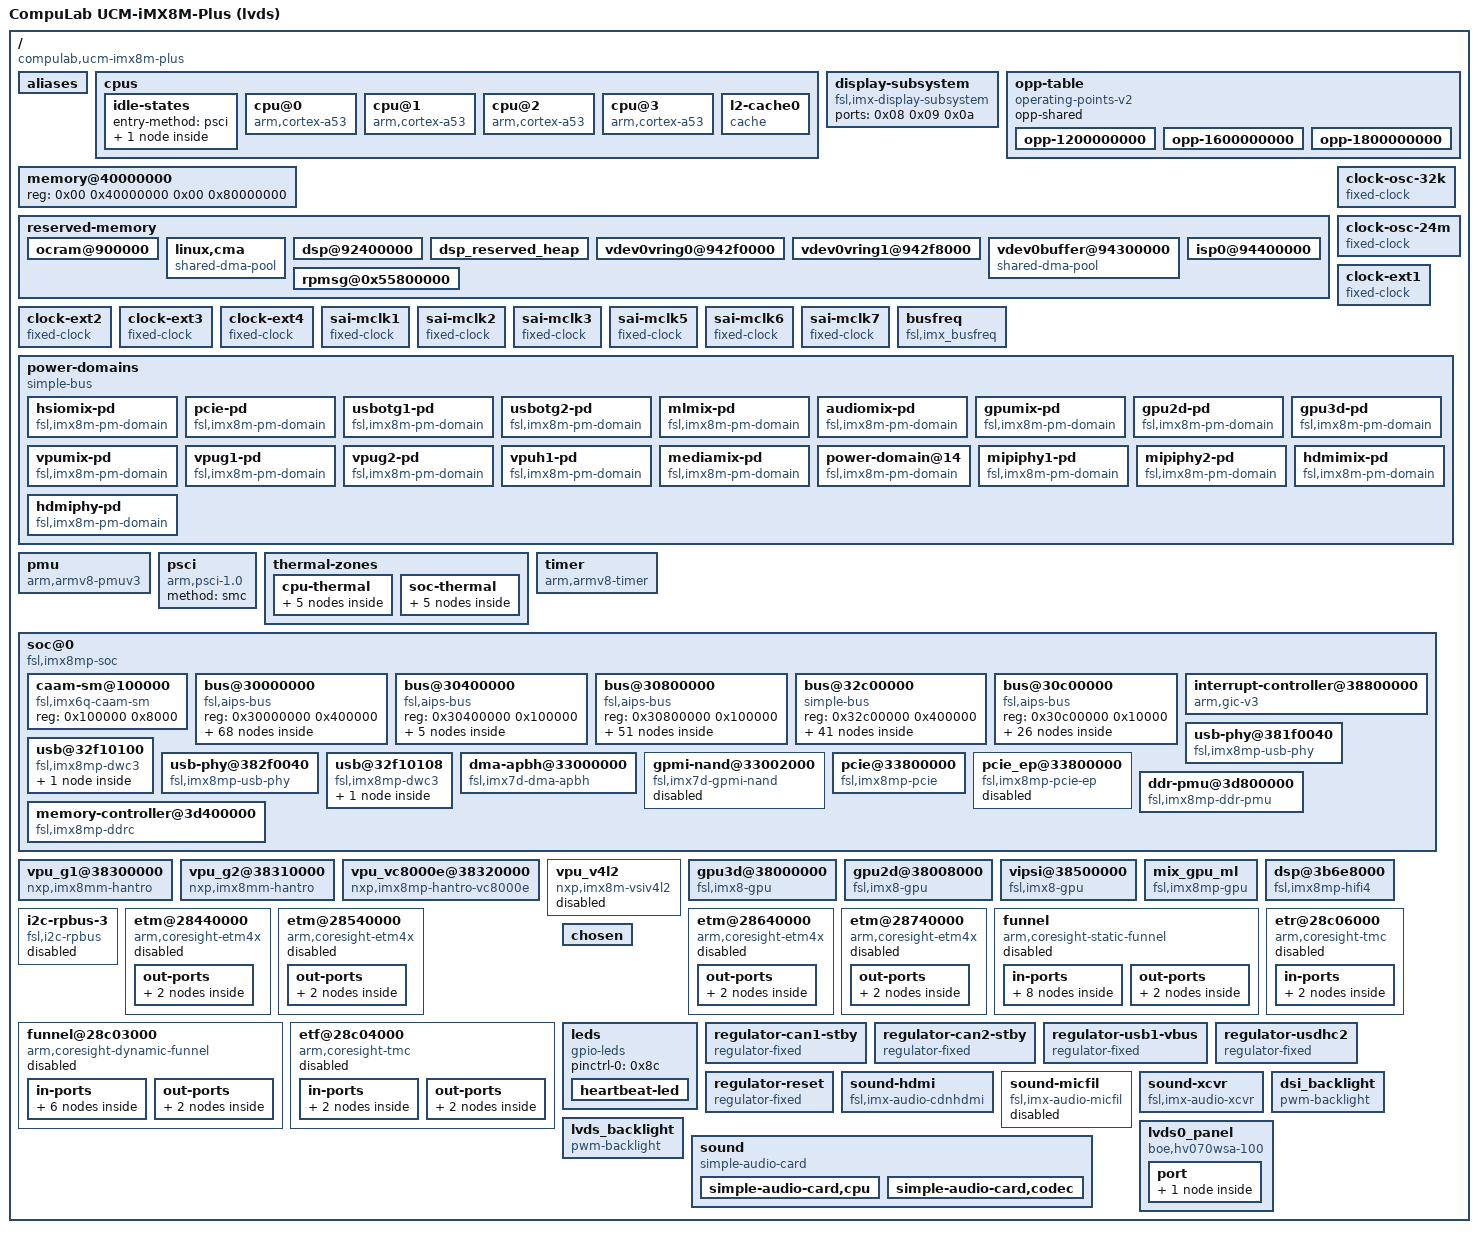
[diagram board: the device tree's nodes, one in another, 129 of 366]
# dtc -I dtb -O dts -o dtb/ucm-imx8m-plus-lvds.dts ucm-imx8m-plus-lvds.dtb
/dts-v1/;

/ {
	interrupt-parent = <0x01>;
	#address-cells = <0x02>;
	#size-cells = <0x02>;
	model = "CompuLab UCM-iMX8M-Plus (lvds)";
	compatible = "compulab,ucm-imx8m-plus\0fsl,imx8mp";

	aliases {
		ethernet0 = "/soc@0/bus@30800000/ethernet@30be0000";
		ethernet1 = "/soc@0/bus@30800000/ethernet@30bf0000";
		gpio0 = "/soc@0/bus@30000000/gpio@30200000";
		gpio1 = "/soc@0/bus@30000000/gpio@30210000";
		gpio2 = "/soc@0/bus@30000000/gpio@30220000";
		gpio3 = "/soc@0/bus@30000000/gpio@30230000";
		gpio4 = "/soc@0/bus@30000000/gpio@30240000";
		i2c0 = "/soc@0/bus@30800000/i2c@30a20000";
		i2c1 = "/soc@0/bus@30800000/i2c@30a30000";
		i2c2 = "/soc@0/bus@30800000/i2c@30a40000";
		i2c3 = "/soc@0/bus@30800000/i2c@30a50000";
		i2c4 = "/soc@0/bus@30800000/i2c@30ad0000";
		i2c5 = "/soc@0/bus@30800000/i2c@30ae0000";
		mmc0 = "/soc@0/bus@30800000/mmc@30b40000";
		mmc1 = "/soc@0/bus@30800000/mmc@30b50000";
		mmc2 = "/soc@0/bus@30800000/mmc@30b60000";
		serial0 = "/soc@0/bus@30800000/serial@30860000";
		serial1 = "/soc@0/bus@30800000/serial@30890000";
		serial2 = "/soc@0/bus@30800000/serial@30880000";
		serial3 = "/soc@0/bus@30800000/serial@30a60000";
		isi0 = "/soc@0/bus@32c00000/camera/isi@32e00000";
		isi1 = "/soc@0/bus@32c00000/camera/isi@32e02000";
		csi0 = "/soc@0/bus@32c00000/camera/csi@32e40000";
		csi1 = "/soc@0/bus@32c00000/camera/csi@32e50000";
		isp0 = "/soc@0/bus@32c00000/camera/isp@32e10000";
		isp1 = "/soc@0/bus@32c00000/camera/isp@32e20000";
	};

	cpus {
		#address-cells = <0x01>;
		#size-cells = <0x00>;

		idle-states {
			entry-method = "psci";

			cpu-pd-wait {
				compatible = "arm,idle-state";
				arm,psci-suspend-param = <0x10033>;
				local-timer-stop;
				entry-latency-us = <0x3e8>;
				exit-latency-us = <0x2bc>;
				min-residency-us = <0xa8c>;
				wakeup-latency-us = <0x5dc>;
				phandle = <0x06>;
			};
		};

		cpu@0 {
			device_type = "cpu";
			compatible = "arm,cortex-a53";
			reg = <0x00>;
			clock-latency = <0xee6c>;
			clocks = <0x02 0x11f>;
			operating-points-v2 = <0x03>;
			nvmem-cells = <0x04>;
			nvmem-cell-names = "speed_grade";
			enable-method = "psci";
			next-level-cache = <0x05>;
			#cooling-cells = <0x02>;
			cpu-idle-states = <0x06>;
			cpu-supply = <0x07>;
			phandle = <0x10>;
		};

		cpu@1 {
			device_type = "cpu";
			compatible = "arm,cortex-a53";
			reg = <0x01>;
			clock-latency = <0xee6c>;
			clocks = <0x02 0x11f>;
			operating-points-v2 = <0x03>;
			enable-method = "psci";
			next-level-cache = <0x05>;
			#cooling-cells = <0x02>;
			cpu-idle-states = <0x06>;
			cpu-supply = <0x07>;
			phandle = <0x11>;
		};

		cpu@2 {
			device_type = "cpu";
			compatible = "arm,cortex-a53";
			reg = <0x02>;
			clock-latency = <0xee6c>;
			clocks = <0x02 0x11f>;
			operating-points-v2 = <0x03>;
			enable-method = "psci";
			next-level-cache = <0x05>;
			#cooling-cells = <0x02>;
			cpu-idle-states = <0x06>;
			cpu-supply = <0x07>;
			phandle = <0x12>;
		};

		cpu@3 {
			device_type = "cpu";
			compatible = "arm,cortex-a53";
			reg = <0x03>;
			clock-latency = <0xee6c>;
			clocks = <0x02 0x11f>;
			operating-points-v2 = <0x03>;
			enable-method = "psci";
			next-level-cache = <0x05>;
			#cooling-cells = <0x02>;
			cpu-idle-states = <0x06>;
			cpu-supply = <0x07>;
			phandle = <0x13>;
		};

		l2-cache0 {
			compatible = "cache";
			phandle = <0x05>;
		};
	};

	display-subsystem {
		compatible = "fsl,imx-display-subsystem";
		ports = <0x08 0x09 0x0a>;
	};

	opp-table {
		compatible = "operating-points-v2";
		opp-shared;
		phandle = <0x03>;

		opp-1200000000 {
			opp-hz = <0x00 0x47868c00>;
			opp-microvolt = <0xcf850>;
			opp-supported-hw = <0x8a0 0x07>;
			clock-latency-ns = <0x249f0>;
			opp-suspend;
		};

		opp-1600000000 {
			opp-hz = <0x00 0x5f5e1000>;
			opp-microvolt = <0xe7ef0>;
			opp-supported-hw = <0xa0 0x07>;
			clock-latency-ns = <0x249f0>;
			opp-suspend;
		};

		opp-1800000000 {
			opp-hz = <0x00 0x6b49d200>;
			opp-microvolt = <0xf4240>;
			opp-supported-hw = <0x20 0x03>;
			clock-latency-ns = <0x249f0>;
			opp-suspend;
		};
	};

	memory@40000000 {
		device_type = "memory";
		reg = <0x00 0x40000000 0x00 0x80000000>;
	};

	reserved-memory {
		#address-cells = <0x02>;
		#size-cells = <0x02>;
		ranges;

		ocram@900000 {
			no-map;
			reg = <0x00 0x900000 0x00 0x70000>;
		};

		linux,cma {
			compatible = "shared-dma-pool";
			reusable;
			size = <0x00 0x2c000000>;
			alloc-ranges = <0x00 0x40000000 0x00 0x80000000>;
			linux,cma-default;
		};

		dsp@92400000 {
			reg = <0x00 0x92400000 0x00 0x1000000>;
			no-map;
			phandle = <0x7d>;
		};

		dsp_reserved_heap {
			reg = <0x00 0x93400000 0x00 0xef0000>;
			no-map;
		};

		vdev0vring0@942f0000 {
			reg = <0x00 0x942f0000 0x00 0x8000>;
			no-map;
			phandle = <0x7b>;
		};

		vdev0vring1@942f8000 {
			reg = <0x00 0x942f8000 0x00 0x8000>;
			no-map;
			phandle = <0x7c>;
		};

		vdev0buffer@94300000 {
			compatible = "shared-dma-pool";
			reg = <0x00 0x94300000 0x00 0x100000>;
			no-map;
			phandle = <0x7a>;
		};

		isp0@94400000 {
			no-map;
			reg = <0x00 0x94400000 0x00 0x10000000>;
			phandle = <0x5a>;
		};

		rpmsg@0x55800000 {
			no-map;
			reg = <0x00 0x55800000 0x00 0x800000>;
		};
	};

	clock-osc-32k {
		compatible = "fixed-clock";
		#clock-cells = <0x00>;
		clock-frequency = <0x8000>;
		clock-output-names = "osc_32k";
		phandle = <0x1c>;
	};

	clock-osc-24m {
		compatible = "fixed-clock";
		#clock-cells = <0x00>;
		clock-frequency = <0x16e3600>;
		clock-output-names = "osc_24m";
		phandle = <0x1d>;
	};

	clock-ext1 {
		compatible = "fixed-clock";
		#clock-cells = <0x00>;
		clock-frequency = <0x7ed6b40>;
		clock-output-names = "clk_ext1";
		phandle = <0x1e>;
	};

	clock-ext2 {
		compatible = "fixed-clock";
		#clock-cells = <0x00>;
		clock-frequency = <0x7ed6b40>;
		clock-output-names = "clk_ext2";
		phandle = <0x1f>;
	};

	clock-ext3 {
		compatible = "fixed-clock";
		#clock-cells = <0x00>;
		clock-frequency = <0x7ed6b40>;
		clock-output-names = "clk_ext3";
		phandle = <0x20>;
	};

	clock-ext4 {
		compatible = "fixed-clock";
		#clock-cells = <0x00>;
		clock-frequency = <0x7ed6b40>;
		clock-output-names = "clk_ext4";
		phandle = <0x21>;
	};

	sai-mclk1 {
		compatible = "fixed-clock";
		#clock-cells = <0x00>;
		clock-frequency = <0x00>;
		clock-output-names = "sai1_mclk";
	};

	sai-mclk2 {
		compatible = "fixed-clock";
		#clock-cells = <0x00>;
		clock-frequency = <0x00>;
		clock-output-names = "sai2_mclk";
	};

	sai-mclk3 {
		compatible = "fixed-clock";
		#clock-cells = <0x00>;
		clock-frequency = <0x00>;
		clock-output-names = "sai3_mclk";
	};

	sai-mclk5 {
		compatible = "fixed-clock";
		#clock-cells = <0x00>;
		clock-frequency = <0x00>;
		clock-output-names = "sai5_mclk";
	};

	sai-mclk6 {
		compatible = "fixed-clock";
		#clock-cells = <0x00>;
		clock-frequency = <0x00>;
		clock-output-names = "sai6_mclk";
	};

	sai-mclk7 {
		compatible = "fixed-clock";
		#clock-cells = <0x00>;
		clock-frequency = <0x00>;
		clock-output-names = "sai7_mclk";
	};

	busfreq {
		compatible = "fsl,imx_busfreq";
		clocks = <0x02 0x29 0x02 0x70 0x02 0x71 0x02 0x71 0x02 0x11e 0x02 0x11d 0x02 0x30 0x02 0x32 0x02 0x3f 0x02 0x67 0x02 0x6b 0x02 0x5d 0x02 0x02 0x02 0x38 0x02 0x15>;
		clock-names = "dram_pll\0dram_alt_src\0dram_apb_src\0dram_apb_pre_div\0dram_core\0dram_alt_root\0sys_pll1_40m\0sys_pll1_100m\0sys_pll2_333m\0noc_div\0ahb_div\0main_axi_src\0osc_24m\0sys_pll1_800m\0dram_pll_div";
	};

	power-domains {
		compatible = "simple-bus";

		hsiomix-pd {
			compatible = "fsl,imx8m-pm-domain";
			active-wakeup;
			rpm-always-on;
			#power-domain-cells = <0x00>;
			domain-index = <0x00>;
			domain-name = "hsiomix";
			phandle = <0x0b>;
		};

		pcie-pd {
			compatible = "fsl,imx8m-pm-domain";
			#power-domain-cells = <0x00>;
			domain-index = <0x01>;
			domain-name = "pcie";
			parent-domains = <0x0b>;
			phandle = <0x6c>;
		};

		usbotg1-pd {
			compatible = "fsl,imx8m-pm-domain";
			#power-domain-cells = <0x00>;
			domain-index = <0x02>;
			domain-name = "usb_otg1";
			parent-domains = <0x0b>;
		};

		usbotg2-pd {
			compatible = "fsl,imx8m-pm-domain";
			#power-domain-cells = <0x00>;
			domain-index = <0x03>;
			domain-name = "usb_otg2";
			parent-domains = <0x0b>;
		};

		mlmix-pd {
			compatible = "fsl,imx8m-pm-domain";
			#power-domain-cells = <0x00>;
			domain-index = <0x04>;
			domain-name = "mlmix";
			clocks = <0x02 0x69 0x02 0x6a 0x02 0x10b>;
			phandle = <0x75>;
		};

		audiomix-pd {
			compatible = "fsl,imx8m-pm-domain";
			#power-domain-cells = <0x00>;
			domain-index = <0x05>;
			domain-name = "audiomix";
			clocks = <0x02 0x13b 0x02 0x13c>;
			phandle = <0x5f>;
		};

		gpumix-pd {
			compatible = "fsl,imx8m-pm-domain";
			#power-domain-cells = <0x00>;
			domain-index = <0x06>;
			domain-name = "gpumix";
			clocks = <0x02 0x107 0x02 0x66 0x02 0x65>;
			phandle = <0x0c>;
		};

		gpu2d-pd {
			compatible = "fsl,imx8m-pm-domain";
			#power-domain-cells = <0x00>;
			domain-index = <0x07>;
			domain-name = "gpu2d";
			parent-domains = <0x0c>;
			clocks = <0x02 0xf7>;
			phandle = <0x74>;
		};

		gpu3d-pd {
			compatible = "fsl,imx8m-pm-domain";
			#power-domain-cells = <0x00>;
			domain-index = <0x08>;
			domain-name = "gpu3d";
			parent-domains = <0x0c>;
			clocks = <0x02 0xf8 0x02 0x134>;
			phandle = <0x73>;
		};

		vpumix-pd {
			compatible = "fsl,imx8m-pm-domain";
			#power-domain-cells = <0x00>;
			domain-index = <0x09>;
			domain-name = "vpumix";
			clocks = <0x02 0x11a>;
			phandle = <0x0d>;
		};

		vpug1-pd {
			compatible = "fsl,imx8m-pm-domain";
			#power-domain-cells = <0x00>;
			domain-index = <0x0a>;
			domain-name = "vpu_g1";
			parent-domains = <0x0d>;
			clocks = <0x02 0x106>;
			phandle = <0x70>;
		};

		vpug2-pd {
			compatible = "fsl,imx8m-pm-domain";
			#power-domain-cells = <0x00>;
			domain-index = <0x0b>;
			domain-name = "vpu_g2";
			parent-domains = <0x0d>;
			clocks = <0x02 0x10a>;
			phandle = <0x71>;
		};

		vpuh1-pd {
			compatible = "fsl,imx8m-pm-domain";
			#power-domain-cells = <0x00>;
			domain-index = <0x0c>;
			domain-name = "vpu_h1";
			parent-domains = <0x0d>;
			clocks = <0x02 0x109>;
			phandle = <0x72>;
		};

		mediamix-pd {
			compatible = "fsl,imx8m-pm-domain";
			#power-domain-cells = <0x00>;
			domain-index = <0x0d>;
			domain-name = "mediamix";
			clocks = <0x02 0x10e 0x02 0x10d>;
			phandle = <0x0e>;
		};

		power-domain@14 {
			compatible = "fsl,imx8m-pm-domain";
			#power-domain-cells = <0x00>;
			domain-index = <0x0e>;
			domain-name = "ispdwp";
			parent-domains = <0x0e>;
			phandle = <0x59>;
		};

		mipiphy1-pd {
			compatible = "fsl,imx8m-pm-domain";
			#power-domain-cells = <0x00>;
			domain-index = <0x0f>;
			domain-name = "mipi_phy1";
			parent-domains = <0x0e>;
			phandle = <0x4e>;
		};

		mipiphy2-pd {
			compatible = "fsl,imx8m-pm-domain";
			#power-domain-cells = <0x00>;
			domain-index = <0x10>;
			domain-name = "mipi_phy2";
			parent-domains = <0x0e>;
			phandle = <0x5d>;
		};

		hdmimix-pd {
			compatible = "fsl,imx8m-pm-domain";
			#power-domain-cells = <0x00>;
			domain-index = <0x11>;
			domain-name = "hdmimix";
			clocks = <0x02 0x116 0x02 0x63 0x02 0xa8>;
			phandle = <0x0f>;
		};

		hdmiphy-pd {
			compatible = "fsl,imx8m-pm-domain";
			#power-domain-cells = <0x00>;
			domain-index = <0x12>;
			domain-name = "hdmi_phy";
			parent-domains = <0x0f>;
			phandle = <0x67>;
		};
	};

	pmu {
		compatible = "arm,armv8-pmuv3";
		interrupt-parent = <0x01>;
		interrupts = <0x01 0x07 0x3f04>;
		interrupt-affinity = <0x10 0x11 0x12 0x13>;
	};

	psci {
		compatible = "arm,psci-1.0";
		method = "smc";
	};

	thermal-zones {

		cpu-thermal {
			polling-delay-passive = <0xfa>;
			polling-delay = <0x7d0>;
			thermal-sensors = <0x14 0x00>;

			trips {

				trip0 {
					temperature = <0x14c08>;
					hysteresis = <0x7d0>;
					type = "passive";
					phandle = <0x15>;
				};

				trip1 {
					temperature = <0x17318>;
					hysteresis = <0x7d0>;
					type = "critical";
				};
			};

			cooling-maps {

				map0 {
					trip = <0x15>;
					cooling-device = <0x10 0xffffffff 0xffffffff 0x11 0xffffffff 0xffffffff 0x12 0xffffffff 0xffffffff 0x13 0xffffffff 0xffffffff>;
				};
			};
		};

		soc-thermal {
			polling-delay-passive = <0xfa>;
			polling-delay = <0x7d0>;
			thermal-sensors = <0x14 0x01>;

			trips {

				trip0 {
					temperature = <0x14c08>;
					hysteresis = <0x7d0>;
					type = "passive";
					phandle = <0x16>;
				};

				trip1 {
					temperature = <0x17318>;
					hysteresis = <0x7d0>;
					type = "critical";
				};
			};

			cooling-maps {

				map0 {
					trip = <0x16>;
					cooling-device = <0x10 0xffffffff 0xffffffff 0x11 0xffffffff 0xffffffff 0x12 0xffffffff 0xffffffff 0x13 0xffffffff 0xffffffff>;
				};
			};
		};
	};

	timer {
		compatible = "arm,armv8-timer";
		interrupts = <0x01 0x0d 0x3f08 0x01 0x0e 0x3f08 0x01 0x0b 0x3f08 0x01 0x0a 0x3f08>;
		clock-frequency = <0x7a1200>;
		arm,no-tick-in-suspend;
		interrupt-parent = <0x01>;
	};

	soc@0 {
		compatible = "fsl,imx8mp-soc\0simple-bus";
		#address-cells = <0x01>;
		#size-cells = <0x01>;
		ranges = <0x00 0x00 0x00 0x3e000000>;
		nvmem-cells = <0x17>;
		nvmem-cell-names = "soc_unique_id";

		caam-sm@100000 {
			compatible = "fsl,imx6q-caam-sm";
			reg = <0x100000 0x8000>;
		};

		bus@30000000 {
			compatible = "fsl,aips-bus\0simple-bus";
			reg = <0x30000000 0x400000>;
			#address-cells = <0x01>;
			#size-cells = <0x01>;
			ranges;

			gpio@30200000 {
				compatible = "fsl,imx8mp-gpio\0fsl,imx35-gpio";
				reg = <0x30200000 0x10000>;
				interrupts = <0x00 0x40 0x04 0x00 0x41 0x04>;
				clocks = <0x02 0xc1>;
				gpio-controller;
				#gpio-cells = <0x02>;
				interrupt-controller;
				#interrupt-cells = <0x02>;
				gpio-ranges = <0x18 0x00 0x05 0x1e>;
				phandle = <0x32>;
			};

			gpio@30210000 {
				compatible = "fsl,imx8mp-gpio\0fsl,imx35-gpio";
				reg = <0x30210000 0x10000>;
				interrupts = <0x00 0x42 0x04 0x00 0x43 0x04>;
				clocks = <0x02 0xc2>;
				gpio-controller;
				#gpio-cells = <0x02>;
				interrupt-controller;
				#interrupt-cells = <0x02>;
				gpio-ranges = <0x18 0x00 0x23 0x15>;
				phandle = <0x3b>;
			};

			gpio@30220000 {
				compatible = "fsl,imx8mp-gpio\0fsl,imx35-gpio";
				reg = <0x30220000 0x10000>;
				interrupts = <0x00 0x44 0x04 0x00 0x45 0x04>;
				clocks = <0x02 0xc3>;
				gpio-controller;
				#gpio-cells = <0x02>;
				interrupt-controller;
				#interrupt-cells = <0x02>;
				gpio-ranges = <0x18 0x00 0x38 0x1a 0x18 0x1a 0x90 0x04>;
			};

			gpio@30230000 {
				compatible = "fsl,imx8mp-gpio\0fsl,imx35-gpio";
				reg = <0x30230000 0x10000>;
				interrupts = <0x00 0x46 0x04 0x00 0x47 0x04>;
				clocks = <0x02 0xc4>;
				gpio-controller;
				#gpio-cells = <0x02>;
				interrupt-controller;
				#interrupt-cells = <0x02>;
				gpio-ranges = <0x18 0x00 0x52 0x20>;
				phandle = <0x37>;
			};

			gpio@30240000 {
				compatible = "fsl,imx8mp-gpio\0fsl,imx35-gpio";
				reg = <0x30240000 0x10000>;
				interrupts = <0x00 0x48 0x04 0x00 0x49 0x04>;
				clocks = <0x02 0xc5>;
				gpio-controller;
				#gpio-cells = <0x02>;
				interrupt-controller;
				#interrupt-cells = <0x02>;
				gpio-ranges = <0x18 0x00 0x72 0x1e>;
				phandle = <0x27>;
			};

			tmu@30260000 {
				compatible = "fsl,imx8mp-tmu";
				reg = <0x30260000 0x10000>;
				clocks = <0x02 0x119>;
				#thermal-sensor-cells = <0x01>;
				phandle = <0x14>;
			};

			watchdog@30280000 {
				compatible = "fsl,imx8mp-wdt\0fsl,imx21-wdt";
				reg = <0x30280000 0x10000>;
				interrupts = <0x00 0x4e 0x04>;
				clocks = <0x02 0x103>;
				status = "okay";
				pinctrl-names = "default";
				pinctrl-0 = <0x19>;
				fsl,ext-reset-output;
			};

			pinctrl@30330000 {
				compatible = "fsl,imx8mp-iomuxc";
				reg = <0x30330000 0x10000>;
				pinctrl-names = "default";
				pinctrl-0 = <0x1a>;
				phandle = <0x18>;

				hoggrp {
					fsl,pins = <0x240 0x4a0 0x00 0x00 0x00 0x400001c3 0x244 0x4a4 0x00 0x00 0x00 0x400001c3 0x24c 0x4ac 0x00 0x00 0x00 0x40000019 0x248 0x4a8 0x00 0x00 0x00 0x40000019>;
					phandle = <0x1a>;
				};

				enet1rst {
					fsl,pins = <0x3c 0x29c 0x00 0x00 0x00 0x19>;
					phandle = <0x90>;
				};

				pwm1grp {
					fsl,pins = <0x1dc 0x43c 0x00 0x01 0x00 0x116>;
					phandle = <0x22>;
				};

				pwm2grp {
					fsl,pins = <0x1d8 0x438 0x00 0x01 0x00 0x116>;
					phandle = <0x23>;
				};

				ecspi2grp {
					fsl,pins = <0x1f0 0x450 0x568 0x00 0x01 0x82 0x1f4 0x454 0x570 0x00 0x01 0x82 0x1f8 0x458 0x56c 0x00 0x01 0x82>;
					phandle = <0x25>;
				};

				ecspi2cs {
					fsl,pins = <0x1fc 0x45c 0x00 0x05 0x00 0x40000>;
					phandle = <0x26>;
				};

				eqosgrp {
					fsl,pins = <0x54 0x2b4 0x00 0x00 0x00 0x03 0x58 0x2b8 0x590 0x00 0x01 0x03 0x7c 0x2dc 0x00 0x00 0x00 0x91 0x80 0x2e0 0x00 0x00 0x00 0x91 0x84 0x2e4 0x00 0x00 0x00 0x91 0x88 0x2e8 0x00 0x00 0x00 0x91 0x78 0x2d8 0x00 0x00 0x00 0x91 0x74 0x2d4 0x00 0x00 0x00 0x91 0x68 0x2c8 0x00 0x00 0x00 0x1f 0x64 0x2c4 0x00 0x00 0x00 0x1f 0x60 0x2c0 0x00 0x00 0x00 0x1f 0x5c 0x2bc 0x00 0x00 0x00 0x1f 0x6c 0x2cc 0x00 0x00 0x00 0x1f 0x70 0x2d0 0x00 0x00 0x00 0x1f>;
					phandle = <0x4b>;
				};

				flexcan1grp {
					fsl,pins = <0x1a0 0x400 0x00 0x03 0x00 0x154 0x1ac 0x40c 0x54c 0x03 0x01 0x154>;
					phandle = <0x2c>;
				};

				flexcan2grp {
					fsl,pins = <0x1b0 0x410 0x00 0x03 0x00 0x154 0x1b4 0x414 0x550 0x03 0x01 0x154>;
					phandle = <0x2e>;
				};

				flexcan1reggrp {
					fsl,pins = <0x14 0x274 0x00 0x00 0x00 0x154>;
					phandle = <0x8d>;
				};

				flexcan2reggrp {
					fsl,pins = <0x18 0x278 0x00 0x00 0x00 0x154>;
					phandle = <0x8e>;
				};

				flexspi0grp {
					fsl,pins = <0xe0 0x340 0x00 0x01 0x00 0x1c2 0xe4 0x344 0x00 0x01 0x00 0x82 0xf8 0x358 0x00 0x01 0x00 0x82 0xfc 0x35c 0x00 0x01 0x00 0x82 0x100 0x360 0x00 0x01 0x00 0x82 0x104 0x364 0x00 0x01 0x00 0x82>;
					phandle = <0x48>;
				};

				gpioledgrp {
					fsl,pins = <0x120 0x380 0x00 0x05 0x00 0x19>;
					phandle = <0x8c>;
				};

				i2c1grp {
					fsl,pins = <0x200 0x460 0x5a4 0x00 0x02 0x400001c3 0x204 0x464 0x5a8 0x00 0x02 0x400001c3>;
					phandle = <0x30>;
				};

				i2c2grp {
					fsl,pins = <0x208 0x468 0x5ac 0x00 0x02 0x400001c3 0x20c 0x46c 0x5b0 0x00 0x02 0x400001c3>;
					phandle = <0x33>;
				};

				i2c3grp {
					fsl,pins = <0x210 0x470 0x5b4 0x00 0x04 0x400001c3 0x214 0x474 0x5b8 0x00 0x04 0x400001c3>;
					phandle = <0x35>;
				};

				i2c5grp {
					fsl,pins = <0x144 0x3a4 0x5c8 0x03 0x01 0x400001c3 0x134 0x394 0x5c4 0x03 0x01 0x400001c3>;
					phandle = <0x36>;
				};

				i2c6grp {
					fsl,pins = <0x12c 0x38c 0x5cc 0x03 0x01 0x400001c3 0x130 0x390 0x5d0 0x03 0x01 0x400001c3>;
					phandle = <0x3a>;
				};

				mipi_dsi_en {
					fsl,pins = <0x34 0x294 0x00 0x00 0x00 0x16>;
				};

				pciegrp {
					fsl,pins = <0x218 0x478 0x5a0 0x12 0x00 0x61 0xa4 0x304 0x00 0x05 0x00 0x41 0xa8 0x308 0x00 0x05 0x00 0x41>;
				};

				pmicirq {
					fsl,pins = <0x20 0x280 0x00 0x00 0x00 0x41>;
					phandle = <0x31>;
				};

				typec1grp {
					fsl,pins = <0x194 0x3f4 0x00 0x05 0x00 0x1c4>;
				};

				typec1muxgrp {
					fsl,pins = <0x198 0x3f8 0x00 0x05 0x00 0x16>;
				};

				pdmgrp {
					fsl,pins = <0x130 0x390 0x00 0x04 0x00 0xd6 0x134 0x394 0x4c0 0x04 0x03 0xd6 0x138 0x398 0x4c4 0x04 0x03 0xd6 0x13c 0x39c 0x4c8 0x04 0x03 0xd6 0x140 0x3a0 0x4cc 0x04 0x03 0xd6>;
					phandle = <0x62>;
				};

				sai2grp {
					fsl,pins = <0x1ac 0x40c 0x00 0x00 0x00 0xd6 0x1a8 0x408 0x00 0x00 0x00 0xd6 0x1b0 0x410 0x00 0x00 0x00 0xd6 0x1a4 0x404 0x00 0x00 0x00 0xd6>;
					phandle = <0x60>;
				};

				sai3grp {
					fsl,pins = <0x1c4 0x424 0x4ec 0x00 0x01 0xd6 0x1c8 0x428 0x4e8 0x00 0x01 0xd6 0x1c0 0x420 0x4e4 0x00 0x01 0xd6 0x1cc 0x42c 0x00 0x00 0x00 0xd6 0x1d0 0x430 0x4e0 0x00 0x02 0xd6 0x1b8 0x418 0x00 0x05 0x00 0xd6 0x1bc 0x41c 0x00 0x05 0x00 0xd6>;
					phandle = <0x61>;
				};

				synaptics_dsx_iogrp {
					fsl,pins = <0x38 0x298 0x00 0x00 0x00 0x16>;
				};

				uart1grp {
					fsl,pins = <0x220 0x480 0x5e8 0x00 0x04 0x140 0x224 0x484 0x00 0x00 0x00 0x140 0x230 0x490 0x00 0x01 0x00 0x140 0x234 0x494 0x5e4 0x01 0x05 0x140>;
					phandle = <0x28>;
				};

				uart2grp {
					fsl,pins = <0x228 0x488 0x5f0 0x00 0x06 0x49 0x22c 0x48c 0x00 0x00 0x00 0x49>;
					phandle = <0x2a>;
				};

				uart3grp {
					fsl,pins = <0x1e0 0x440 0x5f8 0x01 0x04 0x140 0x1e4 0x444 0x00 0x01 0x00 0x140 0x1ec 0x44c 0x5f4 0x01 0x03 0x140 0x1e8 0x448 0x00 0x01 0x00 0x140>;
					phandle = <0x29>;
				};

				usb1grp {
					fsl,pins = <0x4c 0x2ac 0x00 0x00 0x00 0x19>;
					phandle = <0x8f>;
				};

				usdhc1grp {
					fsl,pins = <0x8c 0x2ec 0x00 0x00 0x00 0x190 0x90 0x2f0 0x00 0x00 0x00 0x1d0 0x94 0x2f4 0x00 0x00 0x00 0x1d0 0x98 0x2f8 0x00 0x00 0x00 0x1d0 0x9c 0x2fc 0x00 0x00 0x00 0x1d0 0xa0 0x300 0x00 0x00 0x00 0x1d0>;
					phandle = <0x3d>;
				};

				usdhc1grp-100mhz {
					fsl,pins = <0x8c 0x2ec 0x00 0x00 0x00 0x194 0x90 0x2f0 0x00 0x00 0x00 0x1d4 0x94 0x2f4 0x00 0x00 0x00 0x1d4 0x98 0x2f8 0x00 0x00 0x00 0x1d4 0x9c 0x2fc 0x00 0x00 0x00 0x1d4 0xa0 0x300 0x00 0x00 0x00 0x1d4>;
					phandle = <0x3e>;
				};

				usdhc1grp-200mhz {
					fsl,pins = <0x8c 0x2ec 0x00 0x00 0x00 0x196 0x90 0x2f0 0x00 0x00 0x00 0x1d6 0x94 0x2f4 0x00 0x00 0x00 0x1d6 0x98 0x2f8 0x00 0x00 0x00 0x1d6 0x9c 0x2fc 0x00 0x00 0x00 0x1d6 0xa0 0x300 0x00 0x00 0x00 0x1d6>;
					phandle = <0x3f>;
				};

				usdhc2grp-gpio {
					fsl,pins = <0xbc 0x31c 0x00 0x05 0x00 0x1c4 0xd8 0x338 0x00 0x05 0x00 0x41>;
					phandle = <0x41>;
				};

				usdhc2grp {
					fsl,pins = <0xc0 0x320 0x00 0x00 0x00 0x190 0xc4 0x324 0x00 0x00 0x00 0x1d0 0xc8 0x328 0x00 0x00 0x00 0x1d0 0xcc 0x32c 0x00 0x00 0x00 0x1d0 0xd0 0x330 0x00 0x00 0x00 0x1d0 0xd4 0x334 0x00 0x00 0x00 0x1d0 0x24 0x284 0x00 0x01 0x00 0xc1>;
					phandle = <0x40>;
				};

				usdhc2grp-100mhz {
					fsl,pins = <0xc0 0x320 0x00 0x00 0x00 0x194 0xc4 0x324 0x00 0x00 0x00 0x1d4 0xc8 0x328 0x00 0x00 0x00 0x1d4 0xcc 0x32c 0x00 0x00 0x00 0x1d4 0xd0 0x330 0x00 0x00 0x00 0x1d4 0xd4 0x334 0x00 0x00 0x00 0x1d4 0x24 0x284 0x00 0x01 0x00 0xc1>;
					phandle = <0x42>;
				};

				usdhc2grp-200mhz {
					fsl,pins = <0xc0 0x320 0x00 0x00 0x00 0x196 0xc4 0x324 0x00 0x00 0x00 0x1d6 0xc8 0x328 0x00 0x00 0x00 0x1d6 0xcc 0x32c 0x00 0x00 0x00 0x1d6 0xd0 0x330 0x00 0x00 0x00 0x1d6 0xd4 0x334 0x00 0x00 0x00 0x1d6 0x24 0x284 0x00 0x01 0x00 0xc1>;
					phandle = <0x43>;
				};

				usdhc3grp {
					fsl,pins = <0x124 0x384 0x604 0x02 0x01 0x190 0x128 0x388 0x60c 0x02 0x01 0x1d0 0x108 0x368 0x610 0x02 0x01 0x1d0 0x10c 0x36c 0x614 0x02 0x01 0x1d0 0x110 0x370 0x618 0x02 0x01 0x1d0 0x114 0x374 0x61c 0x02 0x01 0x1d0 0x11c 0x37c 0x620 0x02 0x01 0x1d0 0xec 0x34c 0x624 0x02 0x01 0x1d0 0xf0 0x350 0x628 0x02 0x01 0x1d0 0xf4 0x354 0x62c 0x02 0x01 0x1d0 0xe8 0x348 0x630 0x02 0x01 0x190>;
					phandle = <0x45>;
				};

				usdhc3grp-100mhz {
					fsl,pins = <0x124 0x384 0x604 0x02 0x01 0x194 0x128 0x388 0x60c 0x02 0x01 0x1d4 0x108 0x368 0x610 0x02 0x01 0x1d4 0x10c 0x36c 0x614 0x02 0x01 0x1d4 0x110 0x370 0x618 0x02 0x01 0x1d4 0x114 0x374 0x61c 0x02 0x01 0x1d4 0x11c 0x37c 0x620 0x02 0x01 0x1d4 0xec 0x34c 0x624 0x02 0x01 0x1d4 0xf0 0x350 0x628 0x02 0x01 0x1d4 0xf4 0x354 0x62c 0x02 0x01 0x1d4 0xe8 0x348 0x630 0x02 0x01 0x194>;
					phandle = <0x46>;
				};

				usdhc3grp-200mhz {
					fsl,pins = <0x124 0x384 0x604 0x02 0x01 0x196 0x128 0x388 0x60c 0x02 0x01 0x1d6 0x108 0x368 0x610 0x02 0x01 0x1d6 0x10c 0x36c 0x614 0x02 0x01 0x1d6 0x110 0x370 0x618 0x02 0x01 0x1d6 0x114 0x374 0x61c 0x02 0x01 0x1d6 0x11c 0x37c 0x620 0x02 0x01 0x1d6 0xec 0x34c 0x624 0x02 0x01 0x1d6 0xf0 0x350 0x628 0x02 0x01 0x1d6 0xf4 0x354 0x62c 0x02 0x01 0x1d6 0xe8 0x348 0x630 0x02 0x01 0x196>;
					phandle = <0x47>;
				};

				wdoggrp {
					fsl,pins = <0x1c 0x27c 0x00 0x01 0x00 0xc6>;
					phandle = <0x19>;
				};

				csi0_pwn_grp {
					fsl,pins = <0xb8 0x318 0x00 0x05 0x00 0x19>;
				};

				csi_mclk_grp {
					fsl,pins = <0x50 0x2b0 0x00 0x06 0x00 0x59>;
				};

				tsgrp {
					fsl,pins = <0x178 0x3d8 0x00 0x05 0x00 0x00>;
					phandle = <0x38>;
				};

				ts1grp {
					fsl,pins = <0xdc 0x33c 0x00 0x05 0x00 0x00>;
					phandle = <0x3c>;
				};
			};

			iomuxc-gpr@30340000 {
				compatible = "fsl,imx8mp-iomuxc-gpr\0fsl,imx6q-iomuxc-gpr\0syscon";
				reg = <0x30340000 0x10000>;
				phandle = <0x2b>;
			};

			efuse@30350000 {
				compatible = "fsl,imx8mp-ocotp\0fsl,imx8mm-ocotp\0syscon";
				reg = <0x30350000 0x10000>;
				clocks = <0x02 0xd6>;
				#address-cells = <0x01>;
				#size-cells = <0x01>;

				unique-id@420 {
					reg = <0x08 0x08>;
					phandle = <0x17>;
				};

				speed-grade@10 {
					reg = <0x10 0x04>;
					phandle = <0x04>;
				};

				mac-address@640 {
					reg = <0x90 0x06>;
					phandle = <0x49>;
				};

				mac-address@650 {
					reg = <0x96 0x06>;
					phandle = <0x4a>;
				};
			};

			anatop@30360000 {
				compatible = "fsl,imx8mp-anatop\0fsl,imx8mm-anatop\0syscon";
				reg = <0x30360000 0x10000>;
			};

			caam_secvio {
				compatible = "fsl,imx6q-caam-secvio";
				interrupts = <0x00 0x14 0x04>;
				jtag-tamper = "disabled";
				watchdog-tamper = "enabled";
				internal-boot-tamper = "enabled";
				external-pin-tamper = "disabled";
			};

			caam-snvs@30370000 {
				compatible = "fsl,imx6q-caam-snvs";
				reg = <0x30370000 0x10000>;
				clocks = <0x02 0xf9>;
				clock-names = "ipg";
			};

			snvs@30370000 {
				compatible = "fsl,sec-v4.0-mon\0syscon\0simple-mfd";
				reg = <0x30370000 0x10000>;
				phandle = <0x1b>;

				snvs-rtc-lp {
					compatible = "fsl,sec-v4.0-mon-rtc-lp";
					regmap = <0x1b>;
					offset = <0x34>;
					interrupts = <0x00 0x13 0x04 0x00 0x14 0x04>;
					clocks = <0x02 0xf9>;
					clock-names = "snvs-rtc";
				};

				snvs-powerkey {
					compatible = "fsl,sec-v4.0-pwrkey";
					regmap = <0x1b>;
					interrupts = <0x00 0x04 0x04>;
					clocks = <0x02 0xf9>;
					clock-names = "snvs-pwrkey";
					linux,keycode = <0x74>;
					wakeup-source;
					status = "okay";
				};
			};

			clock-controller@30380000 {
				compatible = "fsl,imx8mp-ccm";
				reg = <0x30380000 0x10000>;
				#clock-cells = <0x01>;
				clocks = <0x1c 0x1d 0x1e 0x1f 0x20 0x21>;
				clock-names = "osc_32k\0osc_24m\0clk_ext1\0clk_ext2\0clk_ext3\0clk_ext4";
				assigned-clocks = <0x02 0x42 0x02 0x120 0x02 0x67 0x02 0x68 0x02 0x94 0x02 0x6c 0x02 0x48 0x02 0x12 0x02 0x13 0x02 0x14>;
				assigned-clock-parents = <0x02 0x38 0x02 0x2c 0x02 0x41 0x02 0x38 0x02 0x40 0x02 0x38 0x02 0x38>;
				assigned-clock-rates = <0x00 0x00 0x3b9aca00 0x2faf0800 0x1dcd6500 0x17d78400 0x2faf0800 0x17700000 0x15888000 0x3df582e0>;
				phandle = <0x02>;
			};

			reset-controller@30390000 {
				compatible = "fsl,imx8mp-src\0syscon";
				reg = <0x30390000 0x10000>;
				interrupts = <0x00 0x59 0x04>;
				#reset-cells = <0x01>;
				phandle = <0x6d>;
			};
		};

		bus@30400000 {
			compatible = "fsl,aips-bus\0simple-bus";
			reg = <0x30400000 0x100000>;
			#address-cells = <0x01>;
			#size-cells = <0x01>;
			ranges;

			pwm@30660000 {
				compatible = "fsl,imx8mp-pwm\0fsl,imx27-pwm";
				reg = <0x30660000 0x10000>;
				interrupts = <0x00 0x51 0x04>;
				clocks = <0x02 0xdc 0x02 0xdc>;
				clock-names = "ipg\0per";
				#pwm-cells = <0x02>;
				status = "okay";
				pinctrl-names = "default";
				pinctrl-0 = <0x22>;
				phandle = <0x94>;
			};

			pwm@30670000 {
				compatible = "fsl,imx8mp-pwm\0fsl,imx27-pwm";
				reg = <0x30670000 0x10000>;
				interrupts = <0x00 0x52 0x04>;
				clocks = <0x02 0xdd 0x02 0xdd>;
				clock-names = "ipg\0per";
				#pwm-cells = <0x02>;
				status = "okay";
				pinctrl-names = "default";
				pinctrl-0 = <0x23>;
				phandle = <0x95>;
			};

			pwm@30680000 {
				compatible = "fsl,imx8mp-pwm\0fsl,imx27-pwm";
				reg = <0x30680000 0x10000>;
				interrupts = <0x00 0x53 0x04>;
				clocks = <0x02 0xde 0x02 0xde>;
				clock-names = "ipg\0per";
				#pwm-cells = <0x02>;
				status = "disabled";
			};

			pwm@30690000 {
				compatible = "fsl,imx8mp-pwm\0fsl,imx27-pwm";
				reg = <0x30690000 0x10000>;
				interrupts = <0x00 0x54 0x04>;
				clocks = <0x02 0xdf 0x02 0xdf>;
				clock-names = "ipg\0per";
				#pwm-cells = <0x02>;
				status = "disabled";
			};

			timer@306a0000 {
				compatible = "nxp,sysctr-timer";
				reg = <0x306a0000 0x20000>;
				interrupts = <0x00 0x2f 0x04>;
				clocks = <0x1d>;
				clock-names = "per";
			};
		};

		bus@30800000 {
			compatible = "fsl,aips-bus\0simple-bus";
			reg = <0x30800000 0x100000>;
			#address-cells = <0x01>;
			#size-cells = <0x01>;
			ranges;

			spi@30820000 {
				#address-cells = <0x01>;
				#size-cells = <0x00>;
				compatible = "fsl,imx8mp-ecspi\0fsl,imx6ul-ecspi";
				reg = <0x30820000 0x10000>;
				interrupts = <0x00 0x1f 0x04>;
				clocks = <0x02 0xbd 0x02 0xbd>;
				clock-names = "ipg\0per";
				assigned-clock-rates = <0x4c4b400>;
				assigned-clocks = <0x02 0x95>;
				assigned-clock-parents = <0x02 0x38>;
				dmas = <0x24 0x00 0x07 0x01 0x24 0x01 0x07 0x02>;
				dma-names = "rx\0tx";
				status = "disabled";
			};

			spi@30830000 {
				#address-cells = <0x01>;
				#size-cells = <0x00>;
				compatible = "fsl,imx8mp-ecspi\0fsl,imx6ul-ecspi";
				reg = <0x30830000 0x10000>;
				interrupts = <0x00 0x20 0x04>;
				clocks = <0x02 0xbe 0x02 0xbe>;
				clock-names = "ipg\0per";
				assigned-clock-rates = <0x4c4b400>;
				assigned-clocks = <0x02 0x96>;
				assigned-clock-parents = <0x02 0x38>;
				dmas = <0x24 0x02 0x07 0x01 0x24 0x03 0x07 0x02>;
				dma-names = "rx\0tx";
				status = "okay";
				fsl,spi-num-chipselects = <0x01>;
				pinctrl-names = "default";
				pinctrl-0 = <0x25 0x26>;
				cs-gpios = <0x27 0x0d 0x01>;

				spi@0 {
					reg = <0x00>;
					compatible = "rohm,dh2228fv";
					spi-max-frequency = <0x7a120>;
				};
			};

			spi@30840000 {
				#address-cells = <0x01>;
				#size-cells = <0x00>;
				compatible = "fsl,imx8mp-ecspi\0fsl,imx6ul-ecspi";
				reg = <0x30840000 0x10000>;
				interrupts = <0x00 0x21 0x04>;
				clocks = <0x02 0xbf 0x02 0xbf>;
				clock-names = "ipg\0per";
				assigned-clock-rates = <0x4c4b400>;
				assigned-clocks = <0x02 0xb3>;
				assigned-clock-parents = <0x02 0x38>;
				dmas = <0x24 0x04 0x07 0x01 0x24 0x05 0x07 0x02>;
				dma-names = "rx\0tx";
				status = "disabled";
			};

			serial@30860000 {
				compatible = "fsl,imx8mp-uart\0fsl,imx6q-uart";
				reg = <0x30860000 0x10000>;
				interrupts = <0x00 0x1a 0x04>;
				clocks = <0x02 0xfb 0x02 0xfb>;
				clock-names = "ipg\0per";
				dmas = <0x24 0x16 0x04 0x00 0x24 0x17 0x04 0x00>;
				dma-names = "rx\0tx";
				status = "okay";
				pinctrl-names = "default";
				pinctrl-0 = <0x28>;
				assigned-clocks = <0x02 0x8e>;
				assigned-clock-parents = <0x02 0x31>;
				fsl,uart-has-rtscts;
			};

			serial@30880000 {
				compatible = "fsl,imx8mp-uart\0fsl,imx6q-uart";
				reg = <0x30880000 0x10000>;
				interrupts = <0x00 0x1c 0x04>;
				clocks = <0x02 0xfd 0x02 0xfd>;
				clock-names = "ipg\0per";
				dmas = <0x24 0x1a 0x04 0x00 0x24 0x1b 0x04 0x00>;
				dma-names = "rx\0tx";
				status = "okay";
				pinctrl-names = "default";
				pinctrl-0 = <0x29>;
				assigned-clocks = <0x02 0x90>;
				assigned-clock-parents = <0x02 0x31>;
				fsl,uart-has-rtscts;
			};

			serial@30890000 {
				compatible = "fsl,imx8mp-uart\0fsl,imx6q-uart";
				reg = <0x30890000 0x10000>;
				interrupts = <0x00 0x1b 0x04>;
				clocks = <0x02 0xfc 0x02 0xfc>;
				clock-names = "ipg\0per";
				status = "okay";
				pinctrl-names = "default";
				pinctrl-0 = <0x2a>;
			};

			can@308c0000 {
				compatible = "fsl,imx8mp-flexcan\0fsl,imx6q-flexcan";
				reg = <0x308c0000 0x10000>;
				interrupts = <0x00 0x8e 0x04>;
				clocks = <0x02 0x6e 0x02 0xe9>;
				clock-names = "ipg\0per";
				assigned-clocks = <0x02 0x74>;
				assigned-clock-parents = <0x02 0x30>;
				assigned-clock-rates = <0x2625a00>;
				fsl,clk-source = <0x00>;
				fsl,stop-mode = <0x2b 0x10 0x04 0x10 0x14>;
				status = "okay";
				pinctrl-names = "default";
				pinctrl-0 = <0x2c>;
				xceiver-supply = <0x2d>;
			};

			can@308d0000 {
				compatible = "fsl,imx8mp-flexcan\0fsl,imx6q-flexcan";
				reg = <0x308d0000 0x10000>;
				interrupts = <0x00 0x90 0x04>;
				clocks = <0x02 0x6e 0x02 0xea>;
				clock-names = "ipg\0per";
				assigned-clocks = <0x02 0x75>;
				assigned-clock-parents = <0x02 0x30>;
				assigned-clock-rates = <0x2625a00>;
				fsl,clk-source = <0x00>;
				fsl,stop-mode = <0x2b 0x10 0x05 0x10 0x15>;
				status = "okay";
				pinctrl-names = "default";
				pinctrl-0 = <0x2e>;
				xceiver-supply = <0x2f>;
			};

			crypto@30900000 {
				compatible = "fsl,sec-v4.0";
				#address-cells = <0x01>;
				#size-cells = <0x01>;
				reg = <0x30900000 0x40000>;
				ranges = <0x00 0x30900000 0x40000>;
				interrupts = <0x00 0x5b 0x04>;
				clocks = <0x02 0x6b 0x02 0x6e>;
				clock-names = "aclk\0ipg";

				jr@1000 {
					compatible = "fsl,sec-v4.0-job-ring";
					reg = <0x1000 0x1000>;
					interrupts = <0x00 0x69 0x04>;
				};

				jr@2000 {
					compatible = "fsl,sec-v4.0-job-ring";
					reg = <0x2000 0x1000>;
					interrupts = <0x00 0x6a 0x04>;
				};

				jr@3000 {
					compatible = "fsl,sec-v4.0-job-ring";
					reg = <0x3000 0x1000>;
					interrupts = <0x00 0x72 0x04>;
				};
			};

			i2c@30a20000 {
				compatible = "fsl,imx8mp-i2c\0fsl,imx21-i2c";
				#address-cells = <0x01>;
				#size-cells = <0x00>;
				reg = <0x30a20000 0x10000>;
				interrupts = <0x00 0x23 0x04>;
				clocks = <0x02 0xcd>;
				status = "okay";
				clock-frequency = <0x186a0>;
				pinctrl-names = "default";
				pinctrl-0 = <0x30>;

				pca9450@25 {
					reg = <0x25>;
					compatible = "nxp,pca9450c";
					pinctrl-0 = <0x31>;
					interrupt-parent = <0x32>;
					interrupts = <0x03 0x01>;

					regulators {

						BUCK1 {
							regulator-name = "BUCK1";
							regulator-min-microvolt = <0x927c0>;
							regulator-max-microvolt = <0x2160ec>;
							regulator-boot-on;
							regulator-always-on;
							regulator-ramp-delay = <0xc35>;
						};

						BUCK2 {
							regulator-name = "BUCK2";
							regulator-min-microvolt = <0x927c0>;
							regulator-max-microvolt = <0x2160ec>;
							regulator-boot-on;
							regulator-always-on;
							regulator-ramp-delay = <0xc35>;
							nxp,dvs-run-voltage = <0xe7ef0>;
							nxp,dvs-standby-voltage = <0xcf850>;
							phandle = <0x07>;
						};

						BUCK4 {
							regulator-name = "BUCK4";
							regulator-min-microvolt = <0x927c0>;
							regulator-max-microvolt = <0x33e140>;
							regulator-boot-on;
							regulator-always-on;
						};

						BUCK5 {
							regulator-name = "BUCK5";
							regulator-min-microvolt = <0x927c0>;
							regulator-max-microvolt = <0x33e140>;
							regulator-boot-on;
							regulator-always-on;
						};

						BUCK6 {
							regulator-name = "BUCK6";
							regulator-min-microvolt = <0x927c0>;
							regulator-max-microvolt = <0x33e140>;
							regulator-boot-on;
							regulator-always-on;
						};

						LDO1 {
							regulator-name = "LDO1";
							regulator-min-microvolt = <0x186a00>;
							regulator-max-microvolt = <0x325aa0>;
							regulator-boot-on;
							regulator-always-on;
						};

						LDO2 {
							regulator-name = "LDO2";
							regulator-min-microvolt = "\0\f5";
							regulator-max-microvolt = <0x118c30>;
							regulator-boot-on;
							regulator-always-on;
						};

						LDO3 {
							regulator-name = "LDO3";
							regulator-min-microvolt = "\0\f5";
							regulator-max-microvolt = <0x325aa0>;
							regulator-boot-on;
							regulator-always-on;
						};

						LDO4 {
							regulator-name = "LDO4";
							regulator-min-microvolt = "\0\f5";
							regulator-max-microvolt = <0x325aa0>;
							regulator-boot-on;
							regulator-always-on;
						};

						LDO5 {
							regulator-name = "LDO5";
							regulator-min-microvolt = <0x1b7740>;
							regulator-max-microvolt = <0x325aa0>;
							regulator-boot-on;
							regulator-always-on;
						};
					};
				};
			};

			i2c@30a30000 {
				compatible = "fsl,imx8mp-i2c\0fsl,imx21-i2c";
				#address-cells = <0x01>;
				#size-cells = <0x00>;
				reg = <0x30a30000 0x10000>;
				interrupts = <0x00 0x24 0x04>;
				clocks = <0x02 0xce>;
				status = "okay";
				clock-frequency = <0x61a80>;
				pinctrl-names = "default";
				pinctrl-0 = <0x33>;

				wm8731@1a {
					#sound-dai-cells = <0x00>;
					compatible = "wlf,wm8731";
					reg = <0x1a>;
					clocks = <0x34 0x09>;
					clock-names = "mclk";
					wlf,shared-lrclk;
					status = "okay";
					phandle = <0x98>;
				};

				eeprom@50 {
					compatible = "atmel,24c08";
					reg = <0x50>;
					pagesize = <0x10>;
				};

				eeprom@54 {
					compatible = "atmel,24c08";
					reg = <0x54>;
					pagesize = <0x10>;
				};

				pca9555@20 {
					compatible = "nxp,pca9555";
					gpio-controller;
					#gpio-cells = <0x02>;
					reg = <0x20>;
					phandle = <0x39>;
				};

				rtc@69 {
					compatible = "ab1805";
					reg = <0x69>;
					pagesize = <0x10>;
					status = "okay";
				};
			};

			i2c@30a40000 {
				compatible = "fsl,imx8mp-i2c\0fsl,imx21-i2c";
				#address-cells = <0x01>;
				#size-cells = <0x00>;
				reg = <0x30a40000 0x10000>;
				interrupts = <0x00 0x25 0x04>;
				clocks = <0x02 0xcf>;
				status = "disabled";
				clock-frequency = <0x186a0>;
				pinctrl-names = "default";
				pinctrl-0 = <0x35>;

				gpio@20 {
					compatible = "ti,tca6416";
					reg = <0x20>;
					gpio-controller;
					#gpio-cells = <0x02>;
				};
			};

			i2c@30a50000 {
				compatible = "fsl,imx8mp-i2c\0fsl,imx21-i2c";
				#address-cells = <0x01>;
				#size-cells = <0x00>;
				reg = <0x30a50000 0x10000>;
				interrupts = <0x00 0x26 0x04>;
				clocks = <0x02 0xd0>;
				status = "disabled";
			};

			serial@30a60000 {
				compatible = "fsl,imx8mp-uart\0fsl,imx6q-uart";
				reg = <0x30a60000 0x10000>;
				interrupts = <0x00 0x1d 0x04>;
				clocks = <0x02 0xfe 0x02 0xfe>;
				clock-names = "ipg\0per";
				dmas = <0x24 0x1c 0x04 0x00 0x24 0x1d 0x04 0x00>;
				dma-names = "rx\0tx";
				status = "disabled";
			};

			mailbox@30aa0000 {
				compatible = "fsl,imx8mp-mu\0fsl,imx6sx-mu";
				reg = <0x30aa0000 0x10000>;
				interrupts = <0x00 0x58 0x04>;
				clocks = <0x02 0xd5>;
				#mbox-cells = <0x02>;
			};

			i2c@30ad0000 {
				compatible = "fsl,imx8mp-i2c\0fsl,imx21-i2c";
				#address-cells = <0x01>;
				#size-cells = <0x00>;
				reg = <0x30ad0000 0x10000>;
				interrupts = <0x00 0x4c 0x04>;
				clocks = <0x02 0xe7>;
				status = "okay";
				clock-frequency = <0x61a80>;
				pinctrl-names = "default";
				pinctrl-0 = <0x36>;

				goodix_ts@5d {
					compatible = "goodix,gt911";
					reg = <0x5d>;
					interrupt-parent = <0x37>;
					interrupts = <0x0c 0x04>;
					pinctrl-names = "default";
					pinctrl-0 = <0x38>;
					irq-gpios = <0x37 0x0c 0x00>;
					reset-gpios = <0x39 0x05 0x00>;
					status = "okay";
				};
			};

			i2c@30ae0000 {
				compatible = "fsl,imx8mp-i2c\0fsl,imx21-i2c";
				#address-cells = <0x01>;
				#size-cells = <0x00>;
				reg = <0x30ae0000 0x10000>;
				interrupts = <0x00 0x4d 0x04>;
				clocks = <0x02 0xe8>;
				status = "okay";
				clock-frequency = <0x61a80>;
				pinctrl-names = "default";
				pinctrl-0 = <0x3a>;

				goodix_ts@5d {
					compatible = "goodix,gt911";
					reg = <0x5d>;
					interrupt-parent = <0x3b>;
					interrupts = <0x14 0x04>;
					pinctrl-names = "default";
					pinctrl-0 = <0x3c>;
					irq-gpios = <0x3b 0x14 0x00>;
					reset-gpios = <0x39 0x07 0x00>;
					status = "okay";
				};
			};

			mmc@30b40000 {
				compatible = "fsl,imx8mp-usdhc\0fsl,imx8mm-usdhc";
				reg = <0x30b40000 0x10000>;
				interrupts = <0x00 0x16 0x04>;
				clocks = <0x02 0x00 0x02 0x5f 0x02 0x101>;
				clock-names = "ipg\0ahb\0per";
				fsl,tuning-start-tap = <0x14>;
				fsl,tuning-step = <0x02>;
				bus-width = <0x04>;
				status = "disabled";
				assigned-clocks = <0x02 0x88>;
				assigned-clock-rates = <0x17d78400>;
				pinctrl-names = "default\0state_100mhz\0state_200mhz";
				pinctrl-0 = <0x3d>;
				pinctrl-1 = <0x3e>;
				pinctrl-2 = <0x3f>;
				non-removable;
			};

			mmc@30b50000 {
				compatible = "fsl,imx8mp-usdhc\0fsl,imx8mm-usdhc";
				reg = <0x30b50000 0x10000>;
				interrupts = <0x00 0x17 0x04>;
				clocks = <0x02 0x00 0x02 0x5f 0x02 0x102>;
				clock-names = "ipg\0ahb\0per";
				fsl,tuning-start-tap = <0x14>;
				fsl,tuning-step = <0x02>;
				bus-width = <0x04>;
				status = "okay";
				assigned-clocks = <0x02 0x89>;
				assigned-clock-rates = <0x17d78400>;
				pinctrl-names = "default\0state_100mhz\0state_200mhz";
				pinctrl-0 = <0x40 0x41>;
				pinctrl-1 = <0x42 0x41>;
				pinctrl-2 = <0x43 0x41>;
				cd-gpios = <0x3b 0x0c 0x01>;
				vmmc-supply = <0x44>;
			};

			mmc@30b60000 {
				compatible = "fsl,imx8mp-usdhc\0fsl,imx8mm-usdhc";
				reg = <0x30b60000 0x10000>;
				interrupts = <0x00 0x18 0x04>;
				clocks = <0x02 0x00 0x02 0x5f 0x02 0x115>;
				clock-names = "ipg\0ahb\0per";
				fsl,tuning-start-tap = <0x14>;
				fsl,tuning-step = <0x02>;
				bus-width = <0x08>;
				status = "okay";
				assigned-clocks = <0x02 0xa9>;
				assigned-clock-rates = <0x17d78400>;
				pinctrl-names = "default\0state_100mhz\0state_200mhz";
				pinctrl-0 = <0x45>;
				pinctrl-1 = <0x46>;
				pinctrl-2 = <0x47>;
				non-removable;
			};

			spi@30bb0000 {
				#address-cells = <0x01>;
				#size-cells = <0x00>;
				compatible = "nxp,imx8mm-fspi";
				reg = <0x30bb0000 0x10000 0x8000000 0x10000000>;
				reg-names = "fspi_base\0fspi_mmap";
				interrupts = <0x00 0x6b 0x04>;
				clocks = <0x02 0xe2 0x02 0xe2>;
				clock-names = "fspi\0fspi_en";
				assigned-clock-rates = <0x4c4b400>;
				assigned-clocks = <0x02 0x87>;
				status = "okay";
				pinctrl-names = "default";
				pinctrl-0 = <0x48>;

				mt25qu256aba@0 {
					reg = <0x00>;
					#address-cells = <0x01>;
					#size-cells = <0x01>;
					compatible = "jedec,spi-nor";
					spi-max-frequency = <0x4c4b400>;
					spi-tx-bus-width = <0x04>;
					spi-rx-bus-width = <0x04>;
				};
			};

			dma-controller@30bd0000 {
				compatible = "fsl,imx8mq-sdma";
				reg = <0x30bd0000 0x10000>;
				interrupts = <0x00 0x02 0x04>;
				clocks = <0x02 0xec 0x02 0x6b>;
				clock-names = "ipg\0ahb";
				#dma-cells = <0x03>;
				fsl,sdma-ram-script-name = "imx/sdma/sdma-imx7d.bin";
				phandle = <0x24>;
			};

			ethernet@30be0000 {
				compatible = "fsl,imx8mp-fec\0fsl,imx8mq-fec\0fsl,imx6sx-fec";
				reg = <0x30be0000 0x10000>;
				interrupts = <0x00 0x76 0x04 0x00 0x77 0x04 0x00 0x78 0x04 0x00 0x79 0x04>;
				clocks = <0x02 0xc0 0x02 0xf2 0x02 0x84 0x02 0x83 0x02 0x85>;
				clock-names = "ipg\0ahb\0ptp\0enet_clk_ref\0enet_out";
				assigned-clocks = <0x02 0x5e 0x02 0x84 0x02 0x83 0x02 0x85>;
				assigned-clock-parents = <0x02 0x36 0x02 0x3a 0x02 0x3b 0x02 0x39>;
				assigned-clock-rates = <0x00 0x5f5e100 0x7735940 0x00>;
				fsl,num-tx-queues = <0x03>;
				fsl,num-rx-queues = <0x03>;
				nvmem-cells = <0x49>;
				nvmem-cell-names = "mac-address";
				nvmem_macaddr_swap;
				fsl,stop-mode = <0x2b 0x10 0x03>;
				fsl,wakeup_irq = <0x02>;
				status = "disabled";
			};

			ethernet@30bf0000 {
				compatible = "nxp,imx8mp-dwmac-eqos\0snps,dwmac-5.10a";
				reg = <0x30bf0000 0x10000>;
				interrupts = <0x00 0x86 0x04 0x00 0x87 0x04>;
				interrupt-names = "eth_wake_irq\0macirq";
				clocks = <0x02 0xed 0x02 0xe1 0x02 0x82 0x02 0x81>;
				clock-names = "stmmaceth\0pclk\0ptp_ref\0tx";
				assigned-clocks = <0x02 0x5e 0x02 0x82 0x02 0x81>;
				assigned-clock-parents = <0x02 0x36 0x02 0x3a 0x02 0x3b>;
				assigned-clock-rates = <0x00 0x5f5e100 0x7735940>;
				nvmem-cells = <0x4a>;
				nvmem-cell-names = "mac-address";
				nvmem_macaddr_swap;
				intf_mode = <0x2b 0x04>;
				status = "okay";
				pinctrl-names = "default";
				pinctrl-0 = <0x4b>;
				phy-mode = "rgmii-id";
				phy-handle = <0x4c>;

				mdio {
					compatible = "snps,dwmac-mdio";
					#address-cells = <0x01>;
					#size-cells = <0x00>;

					ethernet-phy@0 {
						compatible = "ethernet-phy-ieee802.3-c22";
						reg = <0x00>;
						eee-broken-1000t;
						phandle = <0x4c>;
					};
				};
			};
		};

		bus@32c00000 {
			compatible = "simple-bus";
			reg = <0x32c00000 0x400000>;
			#address-cells = <0x01>;
			#size-cells = <0x01>;
			ranges;

			mipi_dsi@32e60000 {
				#address-cells = <0x01>;
				#size-cells = <0x00>;
				compatible = "fsl,imx8mp-mipi-dsim";
				reg = <0x32e60000 0x10000>;
				clocks = <0x4d 0x00 0x4d 0x01>;
				clock-names = "cfg\0pll-ref";
				assigned-clocks = <0x02 0xab>;
				assigned-clock-parents = <0x02 0x02>;
				assigned-clock-rates = <0xb71b00>;
				interrupts = <0x00 0x12 0x04>;
				power-domains = <0x4e>;
				status = "okay";

				port@0 {

					endpoint {
						remote-endpoint = <0x4f>;
						phandle = <0x50>;
					};
				};

				panel@0 {
					compatible = "startek,kd050hdfia020";
					reg = <0x00>;
					reset-gpio = <0x39 0x04 0x01>;
					dsi-lanes = <0x04>;
					status = "okay";
				};
			};

			lcd-controller@32e80000 {
				#address-cells = <0x01>;
				#size-cells = <0x00>;
				compatible = "fsl,imx8mp-lcdif1";
				reg = <0x32e80000 0x10000>;
				clocks = <0x4d 0x04 0x4d 0x17 0x4d 0x05>;
				clock-names = "pix\0disp-axi\0disp-apb";
				assigned-clocks = <0x02 0xac 0x02 0x61 0x02 0x62>;
				assigned-clock-parents = <0x02 0x28 0x02 0x41 0x02 0x38>;
				assigned-clock-rates = <0x00 0x1dcd6500 0xbebc200>;
				interrupts = <0x00 0x05 0x04>;
				blk-ctl = <0x4d>;
				resets = <0x4d 0x05>;
				power-domains = <0x0e>;
				status = "disabled";

				port@0 {
					reg = <0x00>;
					phandle = <0x08>;

					endpoint {
						remote-endpoint = <0x50>;
						phandle = <0x4f>;
					};
				};
			};

			lcd-controller@32e90000 {
				#address-cells = <0x01>;
				#size-cells = <0x00>;
				compatible = "fsl,imx8mp-lcdif2";
				reg = <0x32e90000 0x10000>;
				clocks = <0x4d 0x0b 0x4d 0x18 0x4d 0x0c>;
				clock-names = "pix\0disp-axi\0disp-apb";
				assigned-clocks = <0x02 0x139 0x02 0x61 0x02 0x62>;
				assigned-clock-parents = <0x02 0x28 0x02 0x41 0x02 0x38>;
				assigned-clock-rates = <0x00 0x1dcd6500 0xbebc200>;
				interrupts = <0x00 0x06 0x04>;
				power-domains = <0x0e>;
				status = "okay";

				port@0 {
					#address-cells = <0x01>;
					#size-cells = <0x00>;
					reg = <0x00>;
					phandle = <0x09>;

					endpoint@0 {
						reg = <0x00>;
						remote-endpoint = <0x51>;
						phandle = <0x54>;
					};

					endpoint@1 {
						reg = <0x01>;
						remote-endpoint = <0x52>;
						phandle = <0x57>;
					};
				};
			};

			media-blk-ctrl@32ec0000 {
				compatible = "fsl,imx8mp-media-blk-ctrl\0syscon";
				reg = <0x32ec0000 0x10000>;
				power-domains = <0x0e>;
				#clock-cells = <0x01>;
				#reset-cells = <0x01>;
				phandle = <0x4d>;
			};

			ldb@32ec005c {
				#address-cells = <0x01>;
				#size-cells = <0x00>;
				compatible = "fsl,imx8mp-ldb";
				clocks = <0x02 0x13a>;
				clock-names = "ldb";
				assigned-clocks = <0x02 0xae>;
				assigned-clock-parents = <0x02 0x28>;
				gpr = <0x4d>;
				power-domains = <0x0e>;
				status = "okay";

				lvds-channel@0 {
					#address-cells = <0x01>;
					#size-cells = <0x00>;
					reg = <0x00>;
					phys = <0x53>;
					phy-names = "ldb_phy";
					status = "okay";
					fsl,data-mapping = "spwg";
					fsl,data-width = <0x18>;

					port@0 {
						reg = <0x00>;

						endpoint {
							remote-endpoint = <0x54>;
							phandle = <0x51>;
						};
					};

					port@1 {
						reg = <0x01>;

						endpoint {
							remote-endpoint = <0x55>;
							phandle = <0x9a>;
						};
					};
				};

				lvds-channel@1 {
					#address-cells = <0x01>;
					#size-cells = <0x00>;
					reg = <0x01>;
					phys = <0x56>;
					phy-names = "ldb_phy";
					status = "disabled";

					port@0 {
						reg = <0x00>;

						endpoint {
							remote-endpoint = <0x57>;
							phandle = <0x52>;
						};
					};
				};
			};

			phy@32ec0128 {
				compatible = "fsl,imx8mp-lvds-phy";
				#address-cells = <0x01>;
				#size-cells = <0x00>;
				gpr = <0x4d>;
				clocks = <0x02 0x10d>;
				clock-names = "apb";
				power-domains = <0x0e>;
				status = "okay";

				port@0 {
					reg = <0x00>;
					#phy-cells = <0x00>;
					phandle = <0x53>;
				};

				port@1 {
					reg = <0x01>;
					#phy-cells = <0x00>;
					phandle = <0x56>;
				};
			};

			media_gpr@32ec0008 {
				compatible = "fsl,imx8mp-iomuxc-gpr\0syscon";
				reg = <0x32ec0008 0x04>;
			};

			gasket@32ec0060 {
				compatible = "fsl,imx8mp-iomuxc-gpr\0syscon";
				reg = <0x32ec0060 0x28>;
				phandle = <0x5b>;
			};

			gasket@32ec0090 {
				compatible = "fsl,imx8mp-iomuxc-gpr\0syscon";
				reg = <0x32ec0090 0x28>;
				phandle = <0x5c>;
			};

			isi_chain@32e02000 {
				compatible = "fsl,imx8mp-iomuxc-gpr\0syscon";
				reg = <0x32e02000 0x04>;
				phandle = <0x58>;
			};

			camera {
				compatible = "fsl,mxc-md\0simple-bus";
				#address-cells = <0x01>;
				#size-cells = <0x01>;
				ranges;
				status = "disabled";

				isi@32e00000 {
					compatible = "fsl,imx8mp-isi\0fsl,imx8mn-isi";
					reg = <0x32e00000 0x2000>;
					interrupts = <0x00 0x10 0x04>;
					interface = <0x02 0x00 0x02>;
					clocks = <0x02 0x61 0x02 0x62 0x02 0x10e 0x02 0x10d 0x4d 0x08 0x4d 0x06 0x4d 0x07>;
					clock-names = "disp_axi\0disp_apb\0disp_axi_root\0disp_apb_root\0media_blk_bus\0media_blk_isi_proc\0media_blk_isi_apb";
					assigned-clocks = <0x02 0x10e 0x02 0x10d>;
					assigned-clock-rates = <0x1dcd6500 0xbebc200>;
					resets = <0x4d 0x06 0x4d 0x07 0x4d 0x08>;
					reset-names = "isi_rst_proc\0isi_rst_apb\0isi_rst_bus";
					power-domains = <0x0e>;
					isi_chain = <0x58>;
					status = "disabled";
					fsl,chain_buf;

					cap_device {
						compatible = "imx-isi-capture";
						status = "okay";
					};

					m2m_device {
						compatible = "imx-isi-m2m";
						status = "disabled";
					};
				};

				isi@32e02000 {
					compatible = "fsl,imx8mp-isi\0fsl,imx8mn-isi";
					reg = <0x32e02000 0x2000>;
					interrupts = <0x00 0x2a 0x04>;
					interface = <0x03 0x00 0x02>;
					clocks = <0x02 0x61 0x02 0x62 0x02 0x10e 0x02 0x10d 0x4d 0x08 0x4d 0x06 0x4d 0x07>;
					clock-names = "disp_axi\0disp_apb\0disp_axi_root\0disp_apb_root\0media_blk_bus\0media_blk_isi_proc\0media_blk_isi_apb";
					assigned-clocks = <0x02 0x10e 0x02 0x10d>;
					assigned-clock-rates = <0x1dcd6500 0xbebc200>;
					resets = <0x4d 0x06 0x4d 0x07 0x4d 0x08>;
					reset-names = "isi_rst_proc\0isi_rst_apb\0isi_rst_bus";
					power-domains = <0x0e>;
					status = "disabled";
					fsl,chain_buf;

					cap_device {
						compatible = "imx-isi-capture";
						status = "okay";
					};
				};

				dwe@32e30000 {
					compatible = "fsl,imx8mp-dwe";
					clocks = <0x4d 0x13 0x4d 0x14 0x4d 0x15>;
					clock-names = "core\0axi\0ahb";
					reg = <0x32e30000 0x10000>;
					interrupts = <0x00 0x64 0x04>;
					power-domains = <0x59>;
					status = "disabled";
				};

				isp@32e10000 {
					compatible = "fsl,imx8mp-isp";
					reg = <0x32e10000 0x10000>;
					interrupts = <0x00 0x4a 0x04>;
					clocks = <0x4d 0x10 0x4d 0x11 0x4d 0x12 0x4d 0x03>;
					clock-names = "core\0axi\0ahb\0sensor";
					assigned-clocks = <0x02 0x138>;
					assigned-clock-parents = <0x02 0x40>;
					assigned-clock-rates = <0x1dcd6500>;
					power-domains = <0x59>;
					id = <0x00>;
					gpr = <0x4d>;
					memory-region = <0x5a>;
					status = "disabled";
				};

				isp@32e20000 {
					compatible = "fsl,imx8mp-isp";
					reg = <0x32e20000 0x10000>;
					interrupts = <0x00 0x4b 0x04>;
					clocks = <0x4d 0x10 0x4d 0x11 0x4d 0x12 0x4d 0x03>;
					clock-names = "core\0axi\0ahb\0sensor";
					assigned-clocks = <0x02 0x138>;
					assigned-clock-parents = <0x02 0x40>;
					assigned-clock-rates = <0x1dcd6500>;
					power-domains = <0x59>;
					id = <0x01>;
					gpr = <0x4d>;
					status = "disabled";
				};

				csi@32e40000 {
					compatible = "fsl,imx8mp-mipi-csi\0fsl,imx8mn-mipi-csi";
					reg = <0x32e40000 0x10000>;
					interrupts = <0x00 0x11 0x04>;
					clock-frequency = <0x1dcd6500>;
					clocks = <0x02 0xaa 0x02 0x61 0x02 0x62 0x4d 0x02 0x4d 0x03>;
					clock-names = "mipi_clk\0disp_axi\0disp_apb\0media_blk_csi_pclk\0media_blk_csi_aclk";
					assigned-clocks = <0x02 0xaa>;
					assigned-clock-parents = <0x02 0x41>;
					assigned-clock-rates = <0x1dcd6500>;
					bus-width = <0x04>;
					csi-gpr = <0x5b>;
					gpr = <0x4d>;
					resets = <0x4d 0x02 0x4d 0x03>;
					reset-names = "csi_rst_pclk\0csi_rst_aclk";
					power-domains = <0x4e>;
					status = "disabled";
					#address-cells = <0x01>;
					#size-cells = <0x00>;
				};

				csi@32e50000 {
					compatible = "fsl,imx8mp-mipi-csi\0fsl,imx8mn-mipi-csi";
					reg = <0x32e50000 0x10000>;
					interrupts = <0x00 0x50 0x04>;
					clock-frequency = <0xfdad680>;
					clocks = <0x02 0xad 0x02 0x61 0x02 0x62 0x4d 0x09 0x4d 0x0a>;
					clock-names = "mipi_clk\0disp_axi\0disp_apb\0media_blk_csi_pclk\0media_blk_csi_aclk";
					assigned-clocks = <0x02 0xad>;
					assigned-clock-parents = <0x02 0x36>;
					assigned-clock-rates = <0xfdad680>;
					bus-width = <0x04>;
					csi-gpr = <0x5c>;
					gpr = <0x4d>;
					resets = <0x4d 0x09 0x4d 0x0a>;
					reset-names = "csi_rst_pclk\0csi_rst_aclk";
					power-domains = <0x5d>;
					status = "disabled";
					#address-cells = <0x01>;
					#size-cells = <0x00>;
				};
			};

			pcie-phy@32f00000 {
				compatible = "fsl,imx8mp-pcie-phy";
				reg = <0x32f00000 0x10000>;
				clocks = <0x02 0x00>;
				clock-names = "phy";
				#phy-cells = <0x00>;
				status = "okay";
				ext_osc = <0x00>;
				phandle = <0x6e>;
			};

			hsio-mix@32f10000 {
				compatible = "fsl,imx8mp-hsio-mix";
				reg = <0x32f10000 0x08>;
				phandle = <0x6f>;
			};
		};

		bus@30c00000 {
			compatible = "fsl,aips-bus\0simple-bus";
			reg = <0x30c00000 0x10000>;
			#address-cells = <0x01>;
			#size-cells = <0x01>;
			ranges;

			spba-bus@30c00000 {
				compatible = "fsl,spba-bus\0simple-bus";
				reg = <0x30c00000 0x100000>;
				#address-cells = <0x01>;
				#size-cells = <0x01>;
				ranges;

				sai@30c10000 {
					compatible = "fsl,imx8mp-sai\0fsl,imx8mm-sai";
					reg = <0x30c10000 0x10000>;
					interrupts = <0x00 0x5f 0x04>;
					clocks = <0x34 0x00 0x02 0x00 0x34 0x01 0x02 0x00 0x02 0x00>;
					clock-names = "bus\0mclk0\0mclk1\0mclk2\0mclk3";
					dmas = <0x5e 0x00 0x02 0x00 0x5e 0x01 0x02 0x00>;
					dma-names = "rx\0tx";
					fsl,shared-interrupt;
					fsl,dataline = <0x00 0xff 0xff>;
					power-domains = <0x5f>;
					status = "disabled";
				};

				sai@30c20000 {
					compatible = "fsl,imx8mp-sai\0fsl,imx8mm-sai";
					reg = <0x30c20000 0x10000>;
					interrupts = <0x00 0x60 0x04>;
					clocks = <0x34 0x04 0x02 0x00 0x34 0x05 0x02 0x00 0x02 0x00>;
					clock-names = "bus\0mclk0\0mclk1\0mclk2\0mclk3";
					dmas = <0x5e 0x02 0x02 0x00 0x5e 0x03 0x02 0x00>;
					dma-names = "rx\0tx";
					fsl,shared-interrupt;
					fsl,dataline = <0x00 0x0f 0x0f>;
					power-domains = <0x5f>;
					status = "disabled";
					#sound-dai-cells = <0x00>;
					pinctrl-names = "default";
					pinctrl-0 = <0x60>;
					assigned-clocks = <0x02 0x7c>;
					assigned-clock-parents = <0x02 0x26>;
					assigned-clock-rates = <0xbb8000>;
				};

				sai@30c30000 {
					compatible = "fsl,imx8mp-sai\0fsl,imx8mm-sai";
					reg = <0x30c30000 0x10000>;
					interrupts = <0x00 0x32 0x04>;
					clocks = <0x34 0x08 0x02 0x00 0x34 0x09 0x02 0x00 0x02 0x00>;
					clock-names = "bus\0mclk0\0mclk1\0mclk2\0mclk3";
					dmas = <0x5e 0x04 0x02 0x00 0x5e 0x05 0x02 0x00>;
					dma-names = "rx\0tx";
					fsl,shared-interrupt;
					fsl,dataline = <0x00 0x03 0x03>;
					power-domains = <0x5f>;
					status = "okay";
					#sound-dai-cells = <0x00>;
					pinctrl-names = "default";
					pinctrl-0 = <0x61>;
					assigned-clocks = <0x02 0x7d>;
					assigned-clock-parents = <0x02 0x26>;
					assigned-clock-rates = <0xbb8000>;
					fsl,sai-mclk-direction-output;
					phandle = <0x97>;
				};

				sai@30c50000 {
					compatible = "fsl,imx8mp-sai\0fsl,imx8mm-sai";
					reg = <0x30c50000 0x10000>;
					interrupts = <0x00 0x5a 0x04>;
					clocks = <0x34 0x0c 0x02 0x00 0x34 0x0d 0x02 0x00 0x02 0x00>;
					clock-names = "bus\0mclk0\0mclk1\0mclk2\0mclk3";
					dmas = <0x5e 0x08 0x02 0x00 0x5e 0x09 0x02 0x00>;
					dma-names = "rx\0tx";
					fsl,shared-interrupt;
					fsl,dataline = <0x00 0x0f 0x0f>;
					power-domains = <0x5f>;
					status = "disabled";
				};

				sai@30c60000 {
					compatible = "fsl,imx8mp-sai\0fsl,imx8mm-sai";
					reg = <0x30c60000 0x10000>;
					interrupts = <0x00 0x5a 0x04>;
					clocks = <0x34 0x10 0x02 0x00 0x34 0x11 0x02 0x00 0x02 0x00>;
					clock-names = "bus\0mclk0\0mclk1\0mclk2\0mclk3";
					dmas = <0x5e 0x0a 0x02 0x00 0x5e 0x0b 0x02 0x00>;
					dma-names = "rx\0tx";
					fsl,shared-interrupt;
					power-domains = <0x5f>;
					status = "disabled";
				};

				sai@30c80000 {
					compatible = "fsl,imx8mp-sai\0fsl,imx8mm-sai";
					reg = <0x30c80000 0x10000>;
					interrupts = <0x00 0x6f 0x04>;
					clocks = <0x34 0x14 0x02 0x00 0x34 0x15 0x02 0x00 0x02 0x00>;
					clock-names = "bus\0mclk0\0mclk1\0mclk2\0mclk3";
					dmas = <0x5e 0x0c 0x02 0x00 0x5e 0x0d 0x02 0x00>;
					dma-names = "rx\0tx";
					fsl,shared-interrupt;
					power-domains = <0x5f>;
					status = "disabled";
				};

				easrc@30c90000 {
					compatible = "fsl,imx8mn-easrc";
					reg = <0x30c90000 0x10000>;
					interrupts = <0x00 0x7a 0x04>;
					clocks = <0x34 0x18>;
					clock-names = "mem";
					dmas = <0x5e 0x10 0x17 0x00 0x5e 0x11 0x17 0x00 0x5e 0x12 0x17 0x00 0x5e 0x13 0x17 0x00 0x5e 0x14 0x17 0x00 0x5e 0x15 0x17 0x00 0x5e 0x16 0x17 0x00 0x5e 0x17 0x17 0x00>;
					dma-names = "ctx0_rx\0ctx0_tx\0ctx1_rx\0ctx1_tx\0ctx2_rx\0ctx2_tx\0ctx3_rx\0ctx3_tx";
					fsl,easrc-ram-script-name = "imx/easrc/easrc-imx8mn.bin";
					fsl,asrc-rate = <0xbb80>;
					fsl,asrc-width = <0x10>;
					power-domains = <0x5f>;
					status = "okay";
				};

				micfil@30ca0000 {
					compatible = "fsl,imx8mp-micfil";
					reg = <0x30ca0000 0x10000>;
					interrupts = <0x00 0x6d 0x04 0x00 0x6e 0x04 0x00 0x2c 0x04 0x00 0x2d 0x04>;
					clocks = <0x34 0x19 0x34 0x27 0x02 0x26 0x02 0x27 0x02 0x06>;
					clock-names = "ipg_clk\0ipg_clk_app\0pll8k\0pll11k\0clkext3";
					dmas = <0x5e 0x18 0x19 0x80000000>;
					dma-names = "rx";
					power-domains = <0x5f>;
					status = "disabled";
					pinctrl-names = "default";
					pinctrl-0 = <0x62>;
					assigned-clocks = <0x02 0xb4>;
					assigned-clock-parents = <0x02 0x26>;
					assigned-clock-rates = <0xbb80000>;
					phandle = <0x92>;
				};

				aud2htx@30cb0000 {
					compatible = "fsl,imx8mp-aud2htx";
					reg = <0x30cb0000 0x10000>;
					interrupts = <0x00 0x82 0x04>;
					clocks = <0x34 0x21>;
					clock-names = "bus";
					dmas = <0x5e 0x1a 0x02 0x00>;
					dma-names = "tx";
					power-domains = <0x5f>;
					status = "okay";
					phandle = <0x91>;
				};

				xcvr@30cc0000 {
					compatible = "fsl,imx8mp-xcvr";
					reg = <0x30cc0000 0x800 0x30cc0800 0x400 0x30cc0c00 0x80 0x30cc0e00 0x80>;
					reg-names = "ram\0regs\0rxfifo\0txfifo";
					interrupts = <0x00 0x80 0x04 0x00 0x81 0x04 0x00 0x92 0x04>;
					clocks = <0x34 0x1f 0x34 0x26 0x34 0x1c 0x34 0x23>;
					clock-names = "ipg\0phy\0spba\0pll_ipg";
					dmas = <0x5e 0x1e 0x02 0x00 0x5e 0x1f 0x02 0x00>;
					dma-names = "rx\0tx";
					resets = <0x34 0x00>;
					power-domains = <0x5f>;
					status = "okay";
					#sound-dai-cells = <0x00>;
					phandle = <0x93>;
				};
			};

			dma-controller@30e00000 {
				compatible = "fsl,imx8mp-sdma\0fsl,imx7d-sdma";
				reg = <0x30e00000 0x10000>;
				interrupts = <0x00 0x22 0x04>;
				clocks = <0x34 0x1b 0x34 0x1b>;
				clock-names = "ipg\0ahb";
				#dma-cells = <0x03>;
				fsl,sdma-ram-script-name = "imx/sdma/sdma-imx7d.bin";
				fsl,ratio-1-1;
				power-domains = <0x5f>;
				status = "disabled";
			};

			dma-controller@30e10000 {
				compatible = "fsl,imx8mp-sdma\0fsl,imx7d-sdma";
				reg = <0x30e10000 0x10000>;
				interrupts = <0x00 0x67 0x04>;
				clocks = <0x02 0x13b 0x02 0x13b>;
				clock-names = "ipg\0ahb";
				#dma-cells = <0x03>;
				fsl,sdma-ram-script-name = "imx/sdma/sdma-imx7d.bin";
				fsl,ratio-1-1;
				power-domains = <0x5f>;
				status = "okay";
				phandle = <0x5e>;
			};

			audio-blk-ctrl@30e20000 {
				compatible = "fsl,imx8mp-audio-blk-ctrl\0syscon";
				reg = <0x30e20000 0x50c>;
				power-domains = <0x5f>;
				#clock-cells = <0x01>;
				#reset-cells = <0x01>;
				assigned-clocks = <0x34 0x39>;
				assigned-clock-parents = <0x34 0x38>;
				phandle = <0x34>;
			};

			audiomix_dsp {
				compatible = "fsl,audiomix-dsp";
				power-domains = <0x5f>;
			};

			mu2@30e60000 {
				compatible = "fsl,imx8-mu-dsp\0fsl,imx6sx-mu";
				reg = <0x30e60000 0x10000>;
				interrupts = <0x00 0x88 0x04>;
				#mbox-cells = <0x02>;
				clocks = <0x34 0x24>;
				status = "okay";
				phandle = <0x79>;
			};

			hdmi-blk-ctrl@32fc0000 {
				compatible = "fsl,imx8mp-hdmi-blk-ctrl\0syscon";
				reg = <0x32fc0000 0x1000>;
				power-domains = <0x0f>;
				#clock-cells = <0x01>;
				#reset-cells = <0x01>;
				status = "okay";
				phandle = <0x63>;
			};

			irqsteer@32fc2000 {
				compatible = "fsl,imx-irqsteer";
				reg = <0x32fc2000 0x1000>;
				interrupts = <0x00 0x2b 0x04>;
				interrupt-controller;
				#interrupt-cells = <0x01>;
				fsl,channel = <0x01>;
				fsl,num-irqs = <0x40>;
				clocks = <0x63 0x06>;
				clock-names = "ipg";
				assigned-clocks = <0x02 0x63>;
				assigned-clock-parents = <0x02 0x33>;
				assigned-clock-rates = <0x7ed6b40>;
				resets = <0x63 0x05>;
				status = "okay";
				phandle = <0x65>;
			};

			hdmi-pai-pvi@32fc4000 {
				compatible = "fsl,imx8mp-hdmi-pavi";
				reg = <0x32fc4000 0x1000>;
				clocks = <0x63 0x20 0x63 0x17>;
				clock-names = "pvi_clk\0pai_clk";
				resets = <0x63 0x02 0x63 0x03>;
				reset-names = "pai_rst\0pvi_rst";
				status = "okay";
			};

			lcd-controller@32fc6000 {
				#address-cells = <0x01>;
				#size-cells = <0x00>;
				compatible = "fsl,imx8mp-lcdif3";
				reg = <0x32fc6000 0x10000>;
				clocks = <0x64 0x00 0x02 0x64 0x02 0x63 0x63 0x00 0x63 0x01 0x63 0x03 0x63 0x05 0x63 0x09 0x63 0x0a 0x63 0x0b 0x63 0x0c 0x63 0x0d 0x63 0x07>;
				clock-names = "pix\0disp-axi\0disp-apb\0mix_apb\0mix_axi\0xtl_24m\0mix_pix\0lcdif_apb\0lcdif_axi\0lcdif_pdi\0lcdif_pix\0lcdif_spu\0noc_hdmi";
				assigned-clocks = <0x02 0x64 0x02 0x63>;
				assigned-clock-parents = <0x02 0x40 0x02 0x33>;
				assigned-clock-rates = <0x1dcd6500 0x7ed6b40>;
				interrupts = <0x08 0x04>;
				interrupt-parent = <0x65>;
				resets = <0x63 0x07>;
				power-domains = <0x0f>;
				status = "disabled";
				thres-low = <0x01 0x02>;
				thres-high = <0x03 0x04>;

				port@0 {
					reg = <0x00>;
					phandle = <0x0a>;

					endpoint {
						remote-endpoint = <0x66>;
						phandle = <0x68>;
					};
				};
			};

			hdmi@32fd8000 {
				compatible = "fsl,imx8mp-hdmi";
				reg = <0x32fd8000 0x7eff>;
				interrupts = <0x00 0x04>;
				interrupt-parent = <0x65>;
				clocks = <0x02 0x63 0x02 0xa7 0x63 0x1d 0x63 0x1b 0x63 0x1a 0x63 0x19 0x63 0x18 0x63 0x15 0x63 0x14 0x63 0x13 0x63 0x0e 0x63 0x24>;
				clock-names = "iahb\0isfr\0phy_int\0prep_clk\0skp_clk\0sfr_clk\0pix_clk\0cec_clk\0apb_clk\0hpi_clk\0fdcc_ref\0pipe_clk";
				assigned-clocks = <0x02 0x63 0x02 0x64 0x02 0xa7>;
				assigned-clock-parents = <0x02 0x33 0x02 0x40 0x02 0x02>;
				assigned-clock-rates = <0x7ed6b40 0x1dcd6500 0x16e3600>;
				phys = <0x64>;
				phy-names = "hdmi";
				resets = <0x63 0x00>;
				gpr = <0x63>;
				power-domains = <0x67>;
				status = "okay";

				port@0 {

					endpoint {
						remote-endpoint = <0x68>;
						phandle = <0x66>;
					};
				};
			};

			hdmiphy@32fdff00 {
				compatible = "fsl,samsung-hdmi-phy";
				reg = <0x32fdff00 0x100>;
				#clock-cells = <0x01>;
				clocks = <0x63 0x1c 0x63 0x03>;
				clock-names = "apb\0ref";
				clock-output-names = "hdmi_phy";
				#phy-cells = <0x00>;
				resets = <0x63 0x01>;
				status = "okay";
				phandle = <0x64>;
			};
		};

		interrupt-controller@38800000 {
			compatible = "arm,gic-v3";
			reg = <0x38800000 0x10000 0x38880000 0xc0000>;
			#interrupt-cells = <0x03>;
			interrupt-controller;
			interrupts = <0x01 0x09 0x04>;
			interrupt-parent = <0x01>;
			phandle = <0x01>;
		};

		usb-phy@381f0040 {
			compatible = "fsl,imx8mp-usb-phy";
			reg = <0x381f0040 0x40>;
			clocks = <0x02 0x100>;
			clock-names = "phy";
			assigned-clocks = <0x02 0x93>;
			assigned-clock-parents = <0x02 0x02>;
			#phy-cells = <0x00>;
			status = "okay";
			fsl,phy-tx-preemp-amp-tune = <0x03>;
			phandle = <0x69>;
		};

		usb@32f10100 {
			compatible = "fsl,imx8mp-dwc3";
			reg = <0x32f10100 0x08>;
			clocks = <0x02 0x10c 0x02 0xff>;
			clock-names = "hsio\0suspend";
			interrupts = <0x00 0x94 0x04>;
			power-domains = <0x0b>;
			#address-cells = <0x01>;
			#size-cells = <0x01>;
			ranges;
			status = "okay";

			dwc3@38100000 {
				compatible = "snps,dwc3";
				reg = <0x38100000 0x10000>;
				clocks = <0x02 0x137 0x02 0x92 0x02 0xff>;
				clock-names = "bus_early\0ref\0suspend";
				assigned-clocks = <0x02 0x137>;
				assigned-clock-parents = <0x02 0x40>;
				assigned-clock-rates = <0x1dcd6500>;
				interrupts = <0x00 0x28 0x04>;
				phys = <0x69 0x69>;
				phy-names = "usb2-phy\0usb3-phy";
				snps,dis-u2-freeclk-exists-quirk;
				snps,usb2-lpm-disable;
				status = "okay";
				dr_mode = "host";
			};
		};

		usb-phy@382f0040 {
			compatible = "fsl,imx8mp-usb-phy";
			reg = <0x382f0040 0x40>;
			clocks = <0x02 0x100>;
			clock-names = "phy";
			assigned-clocks = <0x02 0x93>;
			assigned-clock-parents = <0x02 0x02>;
			#phy-cells = <0x00>;
			status = "okay";
			fsl,phy-tx-preemp-amp-tune = <0x02>;
			phandle = <0x6a>;
		};

		usb@32f10108 {
			compatible = "fsl,imx8mp-dwc3";
			reg = <0x32f10108 0x08>;
			clocks = <0x02 0x10c 0x02 0xff>;
			clock-names = "hsio\0suspend";
			interrupts = <0x00 0x95 0x04>;
			power-domains = <0x0b>;
			#address-cells = <0x01>;
			#size-cells = <0x01>;
			ranges;
			status = "okay";

			dwc3@38200000 {
				compatible = "snps,dwc3";
				reg = <0x38200000 0x10000>;
				clocks = <0x02 0x137 0x02 0x92 0x02 0xff>;
				clock-names = "bus_early\0ref\0suspend";
				assigned-clocks = <0x02 0x137>;
				assigned-clock-parents = <0x02 0x40>;
				assigned-clock-rates = <0x1dcd6500>;
				interrupts = <0x00 0x29 0x04>;
				phys = <0x6a 0x6a>;
				phy-names = "usb2-phy\0usb3-phy";
				snps,dis-u2-freeclk-exists-quirk;
				snps,usb2-lpm-disable;
				status = "okay";
				dr_mode = "host";
			};
		};

		dma-apbh@33000000 {
			compatible = "fsl,imx7d-dma-apbh\0fsl,imx28-dma-apbh";
			reg = <0x33000000 0x2000>;
			interrupts = <0x00 0x0c 0x04 0x00 0x0c 0x04 0x00 0x0c 0x04 0x00 0x0c 0x04>;
			interrupt-names = "gpmi0\0gpmi1\0gpmi2\0gpmi3";
			#dma-cells = <0x01>;
			dma-channels = <0x04>;
			clocks = <0x02 0xe4>;
			phandle = <0x6b>;
		};

		gpmi-nand@33002000 {
			compatible = "fsl,imx7d-gpmi-nand";
			#address-cells = <0x01>;
			#size-cells = <0x01>;
			reg = <0x33002000 0x2000 0x33004000 0x4000>;
			reg-names = "gpmi-nand\0bch";
			interrupts = <0x00 0x0e 0x04>;
			interrupt-names = "bch";
			clocks = <0x02 0xe3 0x02 0xe4>;
			clock-names = "gpmi_io\0gpmi_bch_apb";
			dmas = <0x6b 0x00>;
			dma-names = "rx-tx";
			status = "disabled";
		};

		pcie@33800000 {
			compatible = "fsl,imx8mp-pcie\0snps,dw-pcie";
			reg = <0x33800000 0x400000 0x1ff00000 0x80000>;
			reg-names = "dbi\0config";
			#address-cells = <0x03>;
			#size-cells = <0x02>;
			device_type = "pci";
			ranges = <0x81000000 0x00 0x00 0x1ff80000 0x00 0x10000 0x82000000 0x00 0x18000000 0x18000000 0x00 0x7f00000>;
			num-lanes = <0x01>;
			num-viewport = <0x04>;
			interrupts = <0x00 0x8c 0x04 0x00 0x7f 0x04>;
			interrupt-names = "msi";
			#interrupt-cells = <0x01>;
			interrupt-map-mask = <0x00 0x00 0x00 0x07>;
			interrupt-map = <0x00 0x00 0x00 0x01 0x01 0x00 0x7e 0x04 0x00 0x00 0x00 0x02 0x01 0x00 0x7d 0x04 0x00 0x00 0x00 0x03 0x01 0x00 0x7c 0x04 0x00 0x00 0x00 0x04 0x01 0x00 0x7b 0x04>;
			fsl,max-link-speed = <0x03>;
			linux,pci-domain = <0x00>;
			power-domains = <0x6c>;
			resets = <0x6d 0x18 0x6d 0x19 0x6d 0x1a 0x6d 0x26 0x6d 0x1b>;
			reset-names = "pciephy\0pciephy_perst\0apps\0clkreq\0turnoff";
			phys = <0x6e>;
			phy-names = "pcie-phy";
			fsl,imx8mp-hsio-mix = <0x6f>;
			status = "okay";
			reset-gpio = <0x39 0x00 0x01>;
			ext_osc = <0x00>;
			clocks = <0x02 0x10c 0x02 0x78 0x02 0x137 0x02 0xd9>;
			clock-names = "pcie\0pcie_aux\0pcie_phy\0pcie_bus";
			assigned-clocks = <0x02 0x137 0x02 0x78>;
			assigned-clock-rates = <0x1dcd6500 0x989680>;
			assigned-clock-parents = <0x02 0x40 0x02 0x39>;
		};

		pcie_ep@33800000 {
			compatible = "fsl,imx8mp-pcie-ep";
			reg = <0x33800000 0x400000 0x18000000 0x8000000>;
			reg-names = "regs\0addr_space";
			num-lanes = <0x01>;
			interrupts = <0x00 0x7f 0x04>;
			interrupt-names = "dma";
			fsl,max-link-speed = <0x03>;
			power-domains = <0x6c>;
			resets = <0x6d 0x18 0x6d 0x19 0x6d 0x1a 0x6d 0x26 0x6d 0x1b>;
			reset-names = "pciephy\0pciephy_perst\0apps\0clkreq\0turnoff";
			phys = <0x6e>;
			phy-names = "pcie-phy";
			fsl,imx8mp-hsio-mix = <0x6f>;
			num-ib-windows = <0x04>;
			num-ob-windows = <0x04>;
			status = "disabled";
			ext_osc = <0x00>;
			clocks = <0x02 0x10c 0x02 0x78 0x02 0x137 0x02 0xd9>;
			clock-names = "pcie\0pcie_aux\0pcie_phy\0pcie_bus";
			assigned-clocks = <0x02 0x137 0x02 0x78>;
			assigned-clock-rates = <0x1dcd6500 0x989680>;
			assigned-clock-parents = <0x02 0x40 0x02 0x39>;
		};

		ddr-pmu@3d800000 {
			compatible = "fsl,imx8mp-ddr-pmu\0fsl,imx8m-ddr-pmu";
			reg = <0x3d800000 0x400000>;
			interrupts = <0x00 0x62 0x04>;
		};

		memory-controller@3d400000 {
			compatible = "fsl,imx8mp-ddrc";
			reg = <0x3d400000 0x400000>;
			interrupts = <0x00 0x93 0x04>;
		};
	};

	vpu_g1@38300000 {
		compatible = "nxp,imx8mm-hantro\0nxp,imx8mp-hantro";
		reg = <0x00 0x38300000 0x00 0x100000>;
		reg-names = "regs_hantro";
		interrupts = <0x00 0x07 0x04>;
		interrupt-names = "irq_hantro";
		clocks = <0x02 0x106 0x02 0x11a>;
		clock-names = "clk_hantro\0clk_hantro_bus";
		assigned-clocks = <0x02 0x72 0x02 0x60>;
		assigned-clock-parents = <0x02 0x38 0x02 0x38>;
		assigned-clock-rates = <0x2faf0800 0x2faf0800>;
		power-domains = <0x70>;
		status = "okay";
	};

	vpu_g2@38310000 {
		compatible = "nxp,imx8mm-hantro\0nxp,imx8mp-hantro";
		reg = <0x00 0x38310000 0x00 0x100000>;
		reg-names = "regs_hantro";
		interrupts = <0x00 0x08 0x04>;
		interrupt-names = "irq_hantro";
		clocks = <0x02 0x10a 0x02 0x11a>;
		clock-names = "clk_hantro\0clk_hantro_bus";
		assigned-clocks = <0x02 0x73 0x02 0x60 0x02 0x17>;
		assigned-clock-parents = <0x02 0x2b 0x02 0x38>;
		assigned-clock-rates = <0x29b92700 0x2faf0800 0x29b92700>;
		power-domains = <0x71>;
		status = "okay";
	};

	vpu_vc8000e@38320000 {
		compatible = "nxp,imx8mp-hantro-vc8000e";
		reg = <0x00 0x38320000 0x00 0x10000>;
		reg-names = "regs_hantro_vc8000e";
		interrupts = <0x00 0x1e 0x04>;
		interrupt-names = "irq_hantro_vc8000e";
		clocks = <0x02 0x109 0x02 0x11a>;
		clock-names = "clk_hantro_vc8000e\0clk_hantro_vc8000e_bus";
		assigned-clocks = <0x02 0xb5 0x02 0x60>;
		assigned-clock-parents = <0x02 0x41 0x02 0x38>;
		assigned-clock-rates = <0x1dcd6500 0x2faf0800>;
		power-domains = <0x72>;
		status = "okay";
	};

	vpu_v4l2 {
		compatible = "nxp,imx8m-vsiv4l2";
		status = "disabled";
	};

	gpu3d@38000000 {
		compatible = "fsl,imx8-gpu";
		reg = <0x00 0x38000000 0x00 0x8000>;
		interrupts = <0x00 0x03 0x04>;
		clocks = <0x02 0xf8 0x02 0x134 0x02 0x65 0x02 0x66>;
		clock-names = "core\0shader\0axi\0ahb";
		assigned-clocks = <0x02 0x133 0x02 0x134 0x02 0x65 0x02 0x66>;
		assigned-clock-parents = <0x02 0x41 0x02 0x41 0x02 0x38 0x02 0x38>;
		assigned-clock-rates = <0x3b9aca00 0x3b9aca00 0x2faf0800 0x17d78400>;
		power-domains = <0x73>;
		status = "okay";
		phandle = <0x76>;
	};

	gpu2d@38008000 {
		compatible = "fsl,imx8-gpu";
		reg = <0x00 0x38008000 0x00 0x8000>;
		interrupts = <0x00 0x19 0x04>;
		clocks = <0x02 0xf7 0x02 0x65 0x02 0x66>;
		clock-names = "core\0axi\0ahb";
		assigned-clocks = <0x02 0x135 0x02 0x65 0x02 0x66>;
		assigned-clock-parents = <0x02 0x41 0x02 0x38 0x02 0x38>;
		assigned-clock-rates = <0x3b9aca00 0x2faf0800 0x17d78400>;
		power-domains = <0x74>;
		status = "okay";
		phandle = <0x78>;
	};

	vipsi@38500000 {
		compatible = "fsl,imx8-gpu\0fsl,imx8-vipsi";
		reg = <0x00 0x38500000 0x00 0x20000>;
		interrupts = <0x00 0x0d 0x04>;
		clocks = <0x02 0x10b 0x02 0x10b 0x02 0x69 0x02 0x6a>;
		clock-names = "core\0shader\0axi\0ahb";
		assigned-clocks = <0x02 0x132 0x02 0x69 0x02 0x6a>;
		assigned-clock-parents = <0x02 0x41 0x02 0x38 0x02 0x38>;
		assigned-clock-rates = <0x3b9aca00 0x2faf0800 0x17d78400>;
		power-domains = <0x75>;
		status = "okay";
		phandle = <0x77>;
	};

	mix_gpu_ml {
		compatible = "fsl,imx8mp-gpu\0fsl,imx8-gpu-ss";
		cores = <0x76 0x77 0x78>;
		reg = <0x00 0x40000000 0x00 0xc0000000 0x00 0x00 0x00 0x10000000>;
		reg-names = "phys_baseaddr\0contiguous_mem";
		status = "okay";
	};

	dsp@3b6e8000 {
		compatible = "fsl,imx8mp-hifi4";
		reg = <0x00 0x3b6e8000 0x00 0x88000>;
		clocks = <0x34 0x20 0x34 0x1d 0x34 0x1e>;
		clock-names = "dsp_clk1\0dsp_clk2\0dsp_clk3";
		firmware-name = "imx/dsp/hifi4.bin";
		power-domains = <0x5f>;
		mbox-names = "tx0\0rx0\0rxdb0";
		mboxes = <0x79 0x00 0x00 0x79 0x01 0x00 0x79 0x03 0x00>;
		memory-region = <0x7a 0x7b 0x7c 0x7d>;
		syscon = <0x34>;
		status = "okay";
	};

	i2c-rpbus-3 {
		compatible = "fsl,i2c-rpbus";
		status = "disabled";
	};

	etm@28440000 {
		compatible = "arm,coresight-etm4x\0arm,primecell";
		reg = <0x00 0x28440000 0x00 0x10000>;
		arm,primecell-periphid = <0xbb95d>;
		cpu = <0x10>;
		clocks = <0x02 0x5d>;
		clock-names = "apb_pclk";
		status = "disabled";

		out-ports {

			port {

				endpoint {
					remote-endpoint = <0x7e>;
					phandle = <0x82>;
				};
			};
		};
	};

	etm@28540000 {
		compatible = "arm,coresight-etm4x\0arm,primecell";
		reg = <0x00 0x28540000 0x00 0x10000>;
		arm,primecell-periphid = <0xbb95d>;
		cpu = <0x11>;
		clocks = <0x02 0x5d>;
		clock-names = "apb_pclk";
		status = "disabled";

		out-ports {

			port {

				endpoint {
					remote-endpoint = <0x7f>;
					phandle = <0x83>;
				};
			};
		};
	};

	etm@28640000 {
		compatible = "arm,coresight-etm4x\0arm,primecell";
		reg = <0x00 0x28640000 0x00 0x10000>;
		arm,primecell-periphid = <0xbb95d>;
		cpu = <0x12>;
		clocks = <0x02 0x5d>;
		clock-names = "apb_pclk";
		status = "disabled";

		out-ports {

			port {

				endpoint {
					remote-endpoint = <0x80>;
					phandle = <0x84>;
				};
			};
		};
	};

	etm@28740000 {
		compatible = "arm,coresight-etm4x\0arm,primecell";
		reg = <0x00 0x28740000 0x00 0x10000>;
		arm,primecell-periphid = <0xbb95d>;
		cpu = <0x13>;
		clocks = <0x02 0x5d>;
		clock-names = "apb_pclk";
		status = "disabled";

		out-ports {

			port {

				endpoint {
					remote-endpoint = <0x81>;
					phandle = <0x85>;
				};
			};
		};
	};

	funnel {
		compatible = "arm,coresight-static-funnel";
		status = "disabled";

		in-ports {
			#address-cells = <0x01>;
			#size-cells = <0x00>;

			port@0 {
				reg = <0x00>;

				endpoint {
					remote-endpoint = <0x82>;
					phandle = <0x7e>;
				};
			};

			port@1 {
				reg = <0x01>;

				endpoint {
					remote-endpoint = <0x83>;
					phandle = <0x7f>;
				};
			};

			port@2 {
				reg = <0x02>;

				endpoint {
					remote-endpoint = <0x84>;
					phandle = <0x80>;
				};
			};

			port@3 {
				reg = <0x03>;

				endpoint {
					remote-endpoint = <0x85>;
					phandle = <0x81>;
				};
			};
		};

		out-ports {

			port {

				endpoint {
					remote-endpoint = <0x86>;
					phandle = <0x87>;
				};
			};
		};
	};

	funnel@28c03000 {
		compatible = "arm,coresight-dynamic-funnel\0arm,primecell";
		reg = <0x00 0x28c03000 0x00 0x1000>;
		clocks = <0x02 0x5d>;
		clock-names = "apb_pclk";
		status = "disabled";

		in-ports {
			#address-cells = <0x01>;
			#size-cells = <0x00>;

			port@0 {
				reg = <0x00>;

				endpoint {
					remote-endpoint = <0x87>;
					phandle = <0x86>;
				};
			};

			port@1 {
				reg = <0x01>;

				endpoint {
				};
			};

			port@2 {
				reg = <0x02>;

				endpoint {
				};
			};
		};

		out-ports {

			port {

				endpoint {
					remote-endpoint = <0x88>;
					phandle = <0x89>;
				};
			};
		};
	};

	etf@28c04000 {
		compatible = "arm,coresight-tmc\0arm,primecell";
		reg = <0x00 0x28c04000 0x00 0x1000>;
		clocks = <0x02 0x5d>;
		clock-names = "apb_pclk";
		status = "disabled";

		in-ports {

			port {

				endpoint {
					remote-endpoint = <0x89>;
					phandle = <0x88>;
				};
			};
		};

		out-ports {

			port {

				endpoint {
					remote-endpoint = <0x8a>;
					phandle = <0x8b>;
				};
			};
		};
	};

	etr@28c06000 {
		compatible = "arm,coresight-tmc\0arm,primecell";
		reg = <0x00 0x28c06000 0x00 0x1000>;
		clocks = <0x02 0x5d>;
		clock-names = "apb_pclk";
		status = "disabled";

		in-ports {

			port {

				endpoint {
					remote-endpoint = <0x8b>;
					phandle = <0x8a>;
				};
			};
		};
	};

	chosen {
		stdout-path = "/soc@0/bus@30800000/serial@30890000";
	};

	leds {
		compatible = "gpio-leds";
		pinctrl-names = "default";
		pinctrl-0 = <0x8c>;

		heartbeat-led {
			label = "Heartbeat";
			gpios = <0x32 0x0c 0x01>;
			linux,default-trigger = "heartbeat";
		};
	};

	regulator-can1-stby {
		compatible = "regulator-fixed";
		regulator-name = "can1-stby";
		pinctrl-names = "default";
		pinctrl-0 = <0x8d>;
		regulator-min-microvolt = <0x325aa0>;
		regulator-max-microvolt = <0x325aa0>;
		gpio = <0x32 0x00 0x00>;
		enable-active-high;
		phandle = <0x2d>;
	};

	regulator-can2-stby {
		compatible = "regulator-fixed";
		regulator-name = "can2-stby";
		pinctrl-names = "default";
		pinctrl-0 = <0x8e>;
		regulator-min-microvolt = <0x325aa0>;
		regulator-max-microvolt = <0x325aa0>;
		gpio = <0x32 0x01 0x00>;
		enable-active-high;
		phandle = <0x2f>;
	};

	regulator-usb1-vbus {
		compatible = "regulator-fixed";
		regulator-name = "usb1_host_vbus";
		pinctrl-names = "default";
		pinctrl-0 = <0x8f>;
		regulator-min-microvolt = <0x4c4b40>;
		regulator-max-microvolt = <0x4c4b40>;
		gpio = <0x32 0x0e 0x00>;
		enable-active-high;
		regulator-always-on;
	};

	regulator-usdhc2 {
		compatible = "regulator-fixed";
		regulator-name = "VSD_3V3";
		regulator-min-microvolt = <0x325aa0>;
		regulator-max-microvolt = <0x325aa0>;
		gpio = <0x3b 0x13 0x00>;
		enable-active-high;
		startup-delay-us = <0x64>;
		off-on-delay-us = <0x2ee0>;
		phandle = <0x44>;
	};

	regulator-reset {
		compatible = "regulator-fixed";
		regulator-name = "enet_rst";
		pinctrl-names = "default";
		pinctrl-0 = <0x90>;
		regulator-min-microvolt = <0x325aa0>;
		regulator-max-microvolt = <0x325aa0>;
		gpio = <0x32 0x0a 0x00>;
		regulator-boot-on;
		enable-active-high;
		regulator-always-on;
	};

	sound-hdmi {
		compatible = "fsl,imx-audio-cdnhdmi";
		model = "audio-hdmi";
		audio-cpu = <0x91>;
		hdmi-out;
		constraint-rate = <0xac44 0x15888 0x2b110 0x7d00 0xbb80 0x17700 0x2ee00>;
		status = "okay";
	};

	sound-micfil {
		compatible = "fsl,imx-audio-micfil";
		model = "imx-audio-micfil";
		cpu-dai = <0x92>;
		status = "disabled";
	};

	sound-xcvr {
		compatible = "fsl,imx-audio-xcvr";
		model = "imx-audio-xcvr";
		cpu-dai = <0x93>;
	};

	dsi_backlight {
		compatible = "pwm-backlight";
		pwms = <0x94 0x00 0x2dc6c0 0x00>;
		brightness-levels = <0x00 0x01 0x02 0x03 0x04 0x05 0x06 0x07 0x08 0x09 0x0a 0x0b 0x0c 0x0d 0x0e 0x0f 0x10 0x11 0x12 0x13 0x14 0x15 0x16 0x17 0x18 0x19 0x1a 0x1b 0x1c 0x1d 0x1e 0x1f 0x20 0x21 0x22 0x23 0x24 0x25 0x26 0x27 0x28 0x29 0x2a 0x2b 0x2c 0x2d 0x2e 0x2f 0x30 0x31 0x32 0x33 0x34 0x35 0x36 0x37 0x38 0x39 0x3a 0x3b 0x3c 0x3d 0x3e 0x3f 0x40 0x41 0x42 0x43 0x44 0x45 0x46 0x47 0x48 0x49 0x4a 0x4b 0x4c 0x4d 0x4e 0x4f 0x50 0x51 0x52 0x53 0x54 0x55 0x56 0x57 0x58 0x59 0x5a 0x5b 0x5c 0x5d 0x5e 0x5f 0x60 0x61 0x62 0x63 0x64 0x65 0x66 0x67 0x68 0x69 0x6a 0x6b 0x6c 0x6d 0x6e 0x6f 0x70 0x71 0x72 0x73 0x74 0x75 0x76 0x77 0x78 0x79 0x7a 0x7b 0x7c 0x7d 0x7e 0x7f 0x80 0x81 0x82 0x83 0x84 0x85 0x86 0x87 0x88 0x89 0x8a 0x8b 0x8c 0x8d 0x8e 0x8f 0x90 0x91 0x92 0x93 0x94 0x95 0x96 0x97 0x98 0x99 0x9a 0x9b 0x9c 0x9d 0x9e 0x9f 0xa0 0xa1 0xa2 0xa3 0xa4 0xa5 0xa6 0xa7 0xa8 0xa9 0xaa 0xab 0xac 0xad 0xae 0xaf 0xb0 0xb1 0xb2 0xb3 0xb4 0xb5 0xb6 0xb7 0xb8 0xb9 0xba 0xbb 0xbc 0xbd 0xbe 0xbf 0xc0 0xc1 0xc2 0xc3 0xc4 0xc5 0xc6 0xc7 0xc8 0xc9 0xca 0xcb 0xcc 0xcd 0xce 0xcf 0xd0 0xd1 0xd2 0xd3 0xd4 0xd5 0xd6 0xd7 0xd8 0xd9 0xda 0xdb 0xdc 0xdd 0xde 0xdf 0xe0 0xe1 0xe2 0xe3 0xe4 0xe5 0xe6 0xe7 0xe8 0xe9 0xea 0xeb 0xec 0xed 0xee 0xef 0xf0 0xf1 0xf2 0xf3 0xf4 0xf5 0xf6 0xf7 0xf8 0xf9 0xfa 0xfb 0xfc 0xfd 0xfe 0xff>;
		default-brightness-level = <0xde>;
		status = "okay";
	};

	lvds_backlight {
		compatible = "pwm-backlight";
		pwms = <0x95 0x00 0x2dc6c0 0x00>;
		brightness-levels = <0x00 0x01 0x02 0x03 0x04 0x05 0x06 0x07 0x08 0x09 0x0a 0x0b 0x0c 0x0d 0x0e 0x0f 0x10 0x11 0x12 0x13 0x14 0x15 0x16 0x17 0x18 0x19 0x1a 0x1b 0x1c 0x1d 0x1e 0x1f 0x20 0x21 0x22 0x23 0x24 0x25 0x26 0x27 0x28 0x29 0x2a 0x2b 0x2c 0x2d 0x2e 0x2f 0x30 0x31 0x32 0x33 0x34 0x35 0x36 0x37 0x38 0x39 0x3a 0x3b 0x3c 0x3d 0x3e 0x3f 0x40 0x41 0x42 0x43 0x44 0x45 0x46 0x47 0x48 0x49 0x4a 0x4b 0x4c 0x4d 0x4e 0x4f 0x50 0x51 0x52 0x53 0x54 0x55 0x56 0x57 0x58 0x59 0x5a 0x5b 0x5c 0x5d 0x5e 0x5f 0x60 0x61 0x62 0x63 0x64 0x65 0x66 0x67 0x68 0x69 0x6a 0x6b 0x6c 0x6d 0x6e 0x6f 0x70 0x71 0x72 0x73 0x74 0x75 0x76 0x77 0x78 0x79 0x7a 0x7b 0x7c 0x7d 0x7e 0x7f 0x80 0x81 0x82 0x83 0x84 0x85 0x86 0x87 0x88 0x89 0x8a 0x8b 0x8c 0x8d 0x8e 0x8f 0x90 0x91 0x92 0x93 0x94 0x95 0x96 0x97 0x98 0x99 0x9a 0x9b 0x9c 0x9d 0x9e 0x9f 0xa0 0xa1 0xa2 0xa3 0xa4 0xa5 0xa6 0xa7 0xa8 0xa9 0xaa 0xab 0xac 0xad 0xae 0xaf 0xb0 0xb1 0xb2 0xb3 0xb4 0xb5 0xb6 0xb7 0xb8 0xb9 0xba 0xbb 0xbc 0xbd 0xbe 0xbf 0xc0 0xc1 0xc2 0xc3 0xc4 0xc5 0xc6 0xc7 0xc8 0xc9 0xca 0xcb 0xcc 0xcd 0xce 0xcf 0xd0 0xd1 0xd2 0xd3 0xd4 0xd5 0xd6 0xd7 0xd8 0xd9 0xda 0xdb 0xdc 0xdd 0xde 0xdf 0xe0 0xe1 0xe2 0xe3 0xe4 0xe5 0xe6 0xe7 0xe8 0xe9 0xea 0xeb 0xec 0xed 0xee 0xef 0xf0 0xf1 0xf2 0xf3 0xf4 0xf5 0xf6 0xf7 0xf8 0xf9 0xfa 0xfb 0xfc 0xfd 0xfe 0xff>;
		default-brightness-level = <0xde>;
		status = "okay";
		phandle = <0x99>;
	};

	sound {
		compatible = "simple-audio-card";
		simple-audio-card,name = "ucm-imx8m-plus";
		simple-audio-card,widgets = "Headphone\0Headphone Jack\0Line\0Line Out\0Microphone\0Mic Jack\0Line\0Line In";
		simple-audio-card,routing = "Headphone Jack\0RHPOUT\0Headphone Jack\0LHPOUT\0MICIN\0Mic Bias\0Mic Bias\0Mic Jack";
		simple-audio-card,format = "i2s";
		simple-audio-card,bitclock-master = <0x96>;
		simple-audio-card,frame-master = <0x96>;

		simple-audio-card,cpu {
			sound-dai = <0x97>;
			system-clock-frequency = <0x00>;
			system-clock-direction = "out";
			phandle = <0x96>;
		};

		simple-audio-card,codec {
			sound-dai = <0x98>;
			system-clock-direction = "in";
			system-clock-type = "mclk";
		};
	};

	lvds0_panel {
		compatible = "boe,hv070wsa-100";
		backlight = <0x99>;
		enable-gpios = <0x39 0x06 0x00>;

		port {

			endpoint {
				remote-endpoint = <0x9a>;
				phandle = <0x55>;
			};
		};
	};
};
